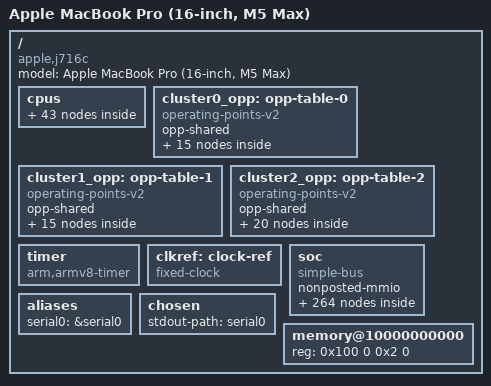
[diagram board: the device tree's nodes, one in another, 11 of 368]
/dts-v1/;


/ {
 compatible = "apple,t6050", "apple,arm-platform";
 #address-cells = <2>;
 #size-cells = <2>;
 cpus {
  #address-cells = <2>;
  #size-cells = <0>;
  cpu-map {
   cluster0 {
    core0 {
     cpu = <&cpu_m00>;
    };
    core1 {
     cpu = <&cpu_m01>;
    };
    core2 {
     cpu = <&cpu_m02>;
    };
    core3 {
     cpu = <&cpu_m03>;
    };
    core4 {
     cpu = <&cpu_m04>;
    };
    core5 {
     cpu = <&cpu_m05>;
    };
   };
   cluster1 {
    core0 {
     cpu = <&cpu_m10>;
    };
    core1 {
     cpu = <&cpu_m11>;
    };
    core2 {
     cpu = <&cpu_m12>;
    };
    core3 {
     cpu = <&cpu_m13>;
    };
    core4 {
     cpu = <&cpu_m14>;
    };
    core5 {
     cpu = <&cpu_m15>;
    };
   };
   cluster2 {
    core0 {
     cpu = <&cpu_p0>;
    };
    core1 {
     cpu = <&cpu_p1>;
    };
    core2 {
     cpu = <&cpu_p2>;
    };
    core3 {
     cpu = <&cpu_p3>;
    };
    core4 {
     cpu = <&cpu_p4>;
    };
    core5 {
     cpu = <&cpu_p5>;
    };
   };
  };
  cpu_m00: cpu@40000 {
   compatible = "apple,sotra-m";
   device_type = "cpu";
   reg = <0x0 0x40000>;
   enable-method = "spin-table";
   cpu-release-addr = <0 0>;
   next-level-cache = <&l2_cache_0>;
   i-cache-size = <0x20000>;
   d-cache-size = <0x10000>;
   operating-points-v2 = <&cluster0_opp>;
   performance-domains = <&cpufreq0>;
   capacity-dmips-mhz = <768>;
   dynamic-power-coefficient = <550>;
  };
  cpu_m01: cpu@40001 {
   compatible = "apple,sotra-m";
   device_type = "cpu";
   reg = <0x0 0x40001>;
   enable-method = "spin-table";
   cpu-release-addr = <0 0>;
   next-level-cache = <&l2_cache_0>;
   i-cache-size = <0x20000>;
   d-cache-size = <0x10000>;
   operating-points-v2 = <&cluster0_opp>;
   performance-domains = <&cpufreq0>;
   capacity-dmips-mhz = <768>;
   dynamic-power-coefficient = <550>;
  };
  cpu_m02: cpu@40002 {
   compatible = "apple,sotra-m";
   device_type = "cpu";
   reg = <0x0 0x40002>;
   enable-method = "spin-table";
   cpu-release-addr = <0 0>;
   next-level-cache = <&l2_cache_0>;
   i-cache-size = <0x20000>;
   d-cache-size = <0x10000>;
   operating-points-v2 = <&cluster0_opp>;
   performance-domains = <&cpufreq0>;
   capacity-dmips-mhz = <768>;
   dynamic-power-coefficient = <550>;
  };
  cpu_m03: cpu@40003 {
   compatible = "apple,sotra-m";
   device_type = "cpu";
   reg = <0x0 0x40003>;
   enable-method = "spin-table";
   cpu-release-addr = <0 0>;
   next-level-cache = <&l2_cache_0>;
   i-cache-size = <0x20000>;
   d-cache-size = <0x10000>;
   operating-points-v2 = <&cluster0_opp>;
   performance-domains = <&cpufreq0>;
   capacity-dmips-mhz = <768>;
   dynamic-power-coefficient = <550>;
  };
  cpu_m04: cpu@40004 {
   compatible = "apple,sotra-m";
   device_type = "cpu";
   reg = <0x0 0x40004>;
   enable-method = "spin-table";
   cpu-release-addr = <0 0>;
   next-level-cache = <&l2_cache_0>;
   i-cache-size = <0x20000>;
   d-cache-size = <0x10000>;
   operating-points-v2 = <&cluster0_opp>;
   performance-domains = <&cpufreq0>;
   capacity-dmips-mhz = <768>;
   dynamic-power-coefficient = <550>;
  };
  cpu_m05: cpu@40005 {
   compatible = "apple,sotra-m";
   device_type = "cpu";
   reg = <0x0 0x40005>;
   enable-method = "spin-table";
   cpu-release-addr = <0 0>;
   next-level-cache = <&l2_cache_0>;
   i-cache-size = <0x20000>;
   d-cache-size = <0x10000>;
   operating-points-v2 = <&cluster0_opp>;
   performance-domains = <&cpufreq0>;
   capacity-dmips-mhz = <768>;
   dynamic-power-coefficient = <550>;
  };
  cpu_m10: cpu@40100 {
   compatible = "apple,sotra-m";
   device_type = "cpu";
   reg = <0x0 0x40100>;
   enable-method = "spin-table";
   cpu-release-addr = <0 0>;
   next-level-cache = <&l2_cache_1>;
   i-cache-size = <0x20000>;
   d-cache-size = <0x10000>;
   operating-points-v2 = <&cluster1_opp>;
   performance-domains = <&cpufreq1>;
   capacity-dmips-mhz = <768>;
   dynamic-power-coefficient = <550>;
  };
  cpu_m11: cpu@40101 {
   compatible = "apple,sotra-m";
   device_type = "cpu";
   reg = <0x0 0x40101>;
   enable-method = "spin-table";
   cpu-release-addr = <0 0>;
   next-level-cache = <&l2_cache_1>;
   i-cache-size = <0x20000>;
   d-cache-size = <0x10000>;
   operating-points-v2 = <&cluster1_opp>;
   performance-domains = <&cpufreq1>;
   capacity-dmips-mhz = <768>;
   dynamic-power-coefficient = <550>;
  };
  cpu_m12: cpu@40102 {
   compatible = "apple,sotra-m";
   device_type = "cpu";
   reg = <0x0 0x40102>;
   enable-method = "spin-table";
   cpu-release-addr = <0 0>;
   next-level-cache = <&l2_cache_1>;
   i-cache-size = <0x20000>;
   d-cache-size = <0x10000>;
   operating-points-v2 = <&cluster1_opp>;
   performance-domains = <&cpufreq1>;
   capacity-dmips-mhz = <768>;
   dynamic-power-coefficient = <550>;
  };
  cpu_m13: cpu@40103 {
   compatible = "apple,sotra-m";
   device_type = "cpu";
   reg = <0x0 0x40103>;
   enable-method = "spin-table";
   cpu-release-addr = <0 0>;
   next-level-cache = <&l2_cache_1>;
   i-cache-size = <0x20000>;
   d-cache-size = <0x10000>;
   operating-points-v2 = <&cluster1_opp>;
   performance-domains = <&cpufreq1>;
   capacity-dmips-mhz = <768>;
   dynamic-power-coefficient = <550>;
  };
  cpu_m14: cpu@40104 {
   compatible = "apple,sotra-m";
   device_type = "cpu";
   reg = <0x0 0x40104>;
   enable-method = "spin-table";
   cpu-release-addr = <0 0>;
   next-level-cache = <&l2_cache_1>;
   i-cache-size = <0x20000>;
   d-cache-size = <0x10000>;
   operating-points-v2 = <&cluster1_opp>;
   performance-domains = <&cpufreq1>;
   capacity-dmips-mhz = <768>;
   dynamic-power-coefficient = <550>;
  };
  cpu_m15: cpu@40105 {
   compatible = "apple,sotra-m";
   device_type = "cpu";
   reg = <0x0 0x40105>;
   enable-method = "spin-table";
   cpu-release-addr = <0 0>;
   next-level-cache = <&l2_cache_1>;
   i-cache-size = <0x20000>;
   d-cache-size = <0x10000>;
   operating-points-v2 = <&cluster1_opp>;
   performance-domains = <&cpufreq1>;
   capacity-dmips-mhz = <768>;
   dynamic-power-coefficient = <550>;
  };
  cpu_p0: cpu@10200 {
   compatible = "apple,sotra-p";
   device_type = "cpu";
   reg = <0x0 0x10200>;
   enable-method = "spin-table";
   cpu-release-addr = <0 0>;
   next-level-cache = <&l2_cache_2>;
   i-cache-size = <0x30000>;
   d-cache-size = <0x20000>;
   operating-points-v2 = <&cluster2_opp>;
   performance-domains = <&cpufreq2>;
   capacity-dmips-mhz = <1024>;
   dynamic-power-coefficient = <1054>;
  };
  cpu_p1: cpu@10201 {
   compatible = "apple,sotra-p";
   device_type = "cpu";
   reg = <0x0 0x10201>;
   enable-method = "spin-table";
   cpu-release-addr = <0 0>;
   next-level-cache = <&l2_cache_2>;
   i-cache-size = <0x30000>;
   d-cache-size = <0x20000>;
   operating-points-v2 = <&cluster2_opp>;
   performance-domains = <&cpufreq2>;
   capacity-dmips-mhz = <1024>;
   dynamic-power-coefficient = <1054>;
  };
  cpu_p2: cpu@10202 {
   compatible = "apple,sotra-p";
   device_type = "cpu";
   reg = <0x0 0x10202>;
   enable-method = "spin-table";
   cpu-release-addr = <0 0>;
   next-level-cache = <&l2_cache_2>;
   i-cache-size = <0x30000>;
   d-cache-size = <0x20000>;
   operating-points-v2 = <&cluster2_opp>;
   performance-domains = <&cpufreq2>;
   capacity-dmips-mhz = <1024>;
   dynamic-power-coefficient = <1054>;
  };
  cpu_p3: cpu@10203 {
   compatible = "apple,sotra-p";
   device_type = "cpu";
   reg = <0x0 0x10203>;
   enable-method = "spin-table";
   cpu-release-addr = <0 0>;
   next-level-cache = <&l2_cache_2>;
   i-cache-size = <0x30000>;
   d-cache-size = <0x20000>;
   operating-points-v2 = <&cluster2_opp>;
   performance-domains = <&cpufreq2>;
   capacity-dmips-mhz = <1024>;
   dynamic-power-coefficient = <1054>;
  };
  cpu_p4: cpu@10204 {
   compatible = "apple,sotra-p";
   device_type = "cpu";
   reg = <0x0 0x10204>;
   enable-method = "spin-table";
   cpu-release-addr = <0 0>;
   next-level-cache = <&l2_cache_2>;
   i-cache-size = <0x30000>;
   d-cache-size = <0x20000>;
   operating-points-v2 = <&cluster2_opp>;
   performance-domains = <&cpufreq2>;
   capacity-dmips-mhz = <1024>;
   dynamic-power-coefficient = <1054>;
  };
  cpu_p5: cpu@10205 {
   compatible = "apple,sotra-p";
   device_type = "cpu";
   reg = <0x0 0x10205>;
   enable-method = "spin-table";
   cpu-release-addr = <0 0>;
   next-level-cache = <&l2_cache_2>;
   i-cache-size = <0x30000>;
   d-cache-size = <0x20000>;
   operating-points-v2 = <&cluster2_opp>;
   performance-domains = <&cpufreq2>;
   capacity-dmips-mhz = <1024>;
   dynamic-power-coefficient = <1054>;
  };
  l2_cache_0: l2-cache-0 {
   compatible = "cache";
   cache-level = <2>;
   cache-unified;
   cache-size = <0x800000>;
  };
  l2_cache_1: l2-cache-1 {
   compatible = "cache";
   cache-level = <2>;
   cache-unified;
   cache-size = <0x800000>;
  };
  l2_cache_2: l2-cache-2 {
   compatible = "cache";
   cache-level = <2>;
   cache-unified;
   cache-size = <0x1000000>;
  };
 };
 cluster0_opp: opp-table-0 {
  compatible = "operating-points-v2";
  opp-shared;
  opp01 {
   opp-hz = /bits/ 64 <1344000000>;
   opp-level = <1>;
   opp-microvolt = <600000>;
   clock-latency-ns = <50000>;
  };
  opp02 {
   opp-hz = /bits/ 64 <1644000000>;
   opp-level = <2>;
   opp-microvolt = <635000>;
   clock-latency-ns = <50000>;
  };
  opp03 {
   opp-hz = /bits/ 64 <1992000000>;
   opp-level = <3>;
   opp-microvolt = <665000>;
   clock-latency-ns = <50000>;
  };
  opp04 {
   opp-hz = /bits/ 64 <2304000000>;
   opp-level = <4>;
   opp-microvolt = <690000>;
   clock-latency-ns = <50000>;
  };
  opp05 {
   opp-hz = /bits/ 64 <2652000000>;
   opp-level = <5>;
   opp-microvolt = <740000>;
   clock-latency-ns = <50000>;
  };
  opp06 {
   opp-hz = /bits/ 64 <2964000000>;
   opp-level = <6>;
   opp-microvolt = <760000>;
   clock-latency-ns = <50000>;
  };
  opp07 {
   opp-hz = /bits/ 64 <3240000000>;
   opp-level = <7>;
   opp-microvolt = <800000>;
   clock-latency-ns = <50000>;
  };
  opp08 {
   opp-hz = /bits/ 64 <3504000000>;
   opp-level = <8>;
   opp-microvolt = <840000>;
   clock-latency-ns = <50000>;
  };
  opp09 {
   opp-hz = /bits/ 64 <3696000000>;
   opp-level = <9>;
   opp-microvolt = <880000>;
   clock-latency-ns = <50000>;
  };
  opp10 {
   opp-hz = /bits/ 64 <3876000000>;
   opp-level = <10>;
   opp-microvolt = <900000>;
   clock-latency-ns = <50000>;
  };
  opp11 {
   opp-hz = /bits/ 64 <4044000000>;
   opp-level = <11>;
   opp-microvolt = <970000>;
   clock-latency-ns = <50000>;
  };
  opp12 {
   opp-hz = /bits/ 64 <4176000000>;
   opp-level = <12>;
   opp-microvolt = <995000>;
   clock-latency-ns = <50000>;
  };
  opp13 {
   opp-hz = /bits/ 64 <4284000000>;
   opp-level = <13>;
   opp-microvolt = <1015000>;
   clock-latency-ns = <50000>;
  };
  opp14 {
   opp-hz = /bits/ 64 <4308000000>;
   opp-level = <14>;
   opp-microvolt = <1015000>;
   clock-latency-ns = <50000>;
  };
  opp15 {
   opp-hz = /bits/ 64 <4380000000>;
   opp-level = <15>;
   opp-microvolt = <1015000>;
   clock-latency-ns = <50000>;
  };
 };
 cluster1_opp: opp-table-1 {
  compatible = "operating-points-v2";
  opp-shared;
  opp01 {
   opp-hz = /bits/ 64 <1344000000>;
   opp-level = <1>;
   opp-microvolt = <600000>;
   clock-latency-ns = <50000>;
  };
  opp02 {
   opp-hz = /bits/ 64 <1644000000>;
   opp-level = <2>;
   opp-microvolt = <635000>;
   clock-latency-ns = <50000>;
  };
  opp03 {
   opp-hz = /bits/ 64 <1992000000>;
   opp-level = <3>;
   opp-microvolt = <665000>;
   clock-latency-ns = <50000>;
  };
  opp04 {
   opp-hz = /bits/ 64 <2304000000>;
   opp-level = <4>;
   opp-microvolt = <690000>;
   clock-latency-ns = <50000>;
  };
  opp05 {
   opp-hz = /bits/ 64 <2652000000>;
   opp-level = <5>;
   opp-microvolt = <740000>;
   clock-latency-ns = <50000>;
  };
  opp06 {
   opp-hz = /bits/ 64 <2964000000>;
   opp-level = <6>;
   opp-microvolt = <760000>;
   clock-latency-ns = <50000>;
  };
  opp07 {
   opp-hz = /bits/ 64 <3240000000>;
   opp-level = <7>;
   opp-microvolt = <800000>;
   clock-latency-ns = <50000>;
  };
  opp08 {
   opp-hz = /bits/ 64 <3504000000>;
   opp-level = <8>;
   opp-microvolt = <840000>;
   clock-latency-ns = <50000>;
  };
  opp09 {
   opp-hz = /bits/ 64 <3696000000>;
   opp-level = <9>;
   opp-microvolt = <880000>;
   clock-latency-ns = <50000>;
  };
  opp10 {
   opp-hz = /bits/ 64 <3876000000>;
   opp-level = <10>;
   opp-microvolt = <900000>;
   clock-latency-ns = <50000>;
  };
  opp11 {
   opp-hz = /bits/ 64 <4044000000>;
   opp-level = <11>;
   opp-microvolt = <970000>;
   clock-latency-ns = <50000>;
  };
  opp12 {
   opp-hz = /bits/ 64 <4176000000>;
   opp-level = <12>;
   opp-microvolt = <1005000>;
   clock-latency-ns = <50000>;
  };
  opp13 {
   opp-hz = /bits/ 64 <4284000000>;
   opp-level = <13>;
   opp-microvolt = <1025000>;
   clock-latency-ns = <50000>;
  };
  opp14 {
   opp-hz = /bits/ 64 <4308000000>;
   opp-level = <14>;
   opp-microvolt = <1025000>;
   clock-latency-ns = <50000>;
  };
  opp15 {
   opp-hz = /bits/ 64 <4380000000>;
   opp-level = <15>;
   opp-microvolt = <1025000>;
   clock-latency-ns = <50000>;
  };
 };
 cluster2_opp: opp-table-2 {
  compatible = "operating-points-v2";
  opp-shared;
  opp01 {
   opp-hz = /bits/ 64 <1308000000>;
   opp-level = <1>;
   opp-microvolt = <625000>;
   clock-latency-ns = <50000>;
  };
  opp02 {
   opp-hz = /bits/ 64 <1620000000>;
   opp-level = <2>;
   opp-microvolt = <675000>;
   clock-latency-ns = <50000>;
  };
  opp03 {
   opp-hz = /bits/ 64 <1980000000>;
   opp-level = <3>;
   opp-microvolt = <700000>;
   clock-latency-ns = <50000>;
  };
  opp04 {
   opp-hz = /bits/ 64 <2292000000>;
   opp-level = <4>;
   opp-microvolt = <735000>;
   clock-latency-ns = <50000>;
  };
  opp05 {
   opp-hz = /bits/ 64 <2580000000>;
   opp-level = <5>;
   opp-microvolt = <775000>;
   clock-latency-ns = <50000>;
  };
  opp06 {
   opp-hz = /bits/ 64 <2880000000>;
   opp-level = <6>;
   opp-microvolt = <810000>;
   clock-latency-ns = <50000>;
  };
  opp07 {
   opp-hz = /bits/ 64 <3180000000>;
   opp-level = <7>;
   opp-microvolt = <840000>;
   clock-latency-ns = <50000>;
  };
  opp08 {
   opp-hz = /bits/ 64 <3432000000>;
   opp-level = <8>;
   opp-microvolt = <875000>;
   clock-latency-ns = <50000>;
  };
  opp09 {
   opp-hz = /bits/ 64 <3648000000>;
   opp-level = <9>;
   opp-microvolt = <890000>;
   clock-latency-ns = <50000>;
  };
  opp10 {
   opp-hz = /bits/ 64 <3828000000>;
   opp-level = <10>;
   opp-microvolt = <925000>;
   clock-latency-ns = <50000>;
  };
  opp11 {
   opp-hz = /bits/ 64 <3984000000>;
   opp-level = <11>;
   opp-microvolt = <960000>;
   clock-latency-ns = <50000>;
  };
  opp12 {
   opp-hz = /bits/ 64 <4104000000>;
   opp-level = <12>;
   opp-microvolt = <980000>;
   clock-latency-ns = <50000>;
  };
  opp13 {
   opp-hz = /bits/ 64 <4188000000>;
   opp-level = <13>;
   opp-microvolt = <1030000>;
   clock-latency-ns = <50000>;
  };
  opp14 {
   opp-hz = /bits/ 64 <4236000000>;
   opp-level = <14>;
   opp-microvolt = <1030000>;
   clock-latency-ns = <50000>;
  };
  opp15 {
   opp-hz = /bits/ 64 <4284000000>;
   opp-level = <15>;
   opp-microvolt = <1030000>;
   clock-latency-ns = <50000>;
  };
  opp16 {
   opp-hz = /bits/ 64 <4308000000>;
   opp-level = <16>;
   opp-microvolt = <1030000>;
   clock-latency-ns = <50000>;
  };
  opp17 {
   opp-hz = /bits/ 64 <4332000000>;
   opp-level = <17>;
   opp-microvolt = <1030000>;
   clock-latency-ns = <50000>;
  };
  opp18 {
   opp-hz = /bits/ 64 <4428000000>;
   opp-level = <18>;
   opp-microvolt = <1030000>;
   clock-latency-ns = <50000>;
  };
  opp19 {
   opp-hz = /bits/ 64 <4512000000>;
   opp-level = <19>;
   opp-microvolt = <1090000>;
   clock-latency-ns = <50000>;
  };
  opp20 {
   opp-hz = /bits/ 64 <4608000000>;
   opp-level = <20>;
   opp-microvolt = <1090000>;
   clock-latency-ns = <50000>;
  };
 };
 timer {
  compatible = "arm,armv8-timer";
  interrupt-parent = <&aic>;
  interrupt-names = "phys", "virt", "hyp-phys", "hyp-virt";
  interrupts = <1 2 4>,
        <1 3 4>,
        <1 0 4>,
        <1 1 4>;
 };
 clkref: clock-ref {
  compatible = "fixed-clock";
  #clock-cells = <0>;
  clock-frequency = <24000000>;
  clock-output-names = "clkref";
 };
 soc: soc {
  compatible = "simple-bus";
  #address-cells = <2>;
  #size-cells = <2>;
  ranges;
  nonposted-mmio;
  cpufreq0: performance-controller@210e20000 {
   compatible = "apple,t6050-cluster-cpufreq", "apple,t8112-cluster-cpufreq";
   reg = <0x2 0x10e20000 0x0 0x1000>;
   #performance-domain-cells = <0>;
  };
  cpufreq1: performance-controller@211e20000 {
   compatible = "apple,t6050-cluster-cpufreq", "apple,t8112-cluster-cpufreq";
   reg = <0x2 0x11e20000 0x0 0x1000>;
   #performance-domain-cells = <0>;
  };
  cpufreq2: performance-controller@212e20000 {
   compatible = "apple,t6050-cluster-cpufreq", "apple,t8112-cluster-cpufreq";
   reg = <0x2 0x12e20000 0x0 0x1000>;
   #performance-domain-cells = <0>;
  };
  aic: interrupt-controller@280400000 {
   compatible = "apple,t6050-aic3", "apple,t8122-aic3";
   #interrupt-cells = <3>;
   interrupt-controller;
   reg = <0x2 0x80400000 0x0 0x1cc000>,
         <0x2 0x80440000 0x0 0x4000>;
   reg-names = "core", "event";
   power-domains = <&ps_aic>;
   affinities {
    m-core-pmu-affinity {
     apple,fiq-index = <4>;
     cpus = <&cpu_m00 &cpu_m01 &cpu_m02 &cpu_m03 &cpu_m04 &cpu_m05 &cpu_m10 &cpu_m11 &cpu_m12 &cpu_m13 &cpu_m14 &cpu_m15>;
    };
    p-core-pmu-affinity {
     apple,fiq-index = <5>;
     cpus = <&cpu_p0 &cpu_p1 &cpu_p2 &cpu_p3 &cpu_p4 &cpu_p5>;
    };
   };
  };
  pmgr: power-management@280600000 {
   compatible = "apple,t6050-pmgr", "apple,t8103-pmgr", "syscon", "simple-mfd";
   #address-cells = <1>;
   #size-cells = <1>;
   reg = <0x2 0x80600000 0x0 0x4000>;
  };
  pmgr1: power-management@280900000 {
   compatible = "apple,t6050-pmgr", "apple,t8103-pmgr", "syscon", "simple-mfd";
   #address-cells = <1>;
   #size-cells = <1>;
   reg = <0x2 0x80900000 0x0 0x4000>;
  };
  pinctrl_nub: pinctrl@2881e4000 {
   compatible = "apple,t6050-pinctrl", "apple,t8103-pinctrl";
   reg = <0x2 0x881e4000 0x0 0x4000>;
   power-domains = <&ps_nub_gpio>;
   gpio-controller;
   #gpio-cells = <2>;
   gpio-ranges = <&pinctrl_nub 0 0 61>;
   apple,npins = <61>;
   interrupt-controller;
   #interrupt-cells = <2>;
   interrupt-parent = <&aic>;
   interrupts = <0 706 4>,
         <0 708 4>,
         <0 710 4>,
         <0 712 4>,
         <0 714 4>,
         <0 716 4>,
         <0 718 4>;
  };
  pmgr_mini: power-management@288300000 {
   compatible = "apple,t6050-pmgr", "apple,t8103-pmgr", "syscon", "simple-mfd";
   #address-cells = <1>;
   #size-cells = <1>;
   reg = <0x2 0x88300000 0x0 0xc000>;
  };
  wdt: watchdog@28836c000 {
   compatible = "apple,t6050-wdt", "apple,t8103-wdt";
   reg = <0x2 0x8836c000 0x0 0x4000>;
   clocks = <&clkref>;
   interrupt-parent = <&aic>;
   interrupts = <0 721 4>;
  };
  smc: smc@28c600000 {
   compatible = "apple,t6050-smc", "apple,t8103-smc";
   reg = <0x2 0x8c600000 0x0 0x4000>,
         <0x2 0x8e000000 0x0 0x100000>;
   reg-names = "smc", "sram";
   mboxes = <&smc_mbox>;
   status = "disabled";
   smc_gpio: gpio {
    compatible = "apple,smc-gpio";
    gpio-controller;
    #gpio-cells = <2>;
   };
   smc_hwmon: hwmon {
    compatible = "apple,smc-hwmon";
   };
  };
  smc_mbox: mbox@28c608000 {
   compatible = "apple,t6050-asc-mailbox", "apple,asc-mailbox-v4";
   reg = <0x2 0x8c608000 0x0 0x4000>;
   interrupt-parent = <&aic>;
   interrupts = <0 899 4>,
         <0 900 4>,
         <0 901 4>,
         <0 902 4>;
   interrupt-names = "send-empty", "send-not-empty",
       "recv-empty", "recv-not-empty";
   #mbox-cells = <0>;
  };
  pinctrl_aop: pinctrl@290824000 {
   compatible = "apple,t6050-pinctrl", "apple,t8103-pinctrl";
   reg = <0x2 0x90824000 0x0 0x4000>;
   gpio-controller;
   #gpio-cells = <2>;
   gpio-ranges = <&pinctrl_aop 0 0 85>;
   apple,npins = <85>;
   interrupt-controller;
   #interrupt-cells = <2>;
   interrupt-parent = <&aic>;
   interrupts = <0 568 4>,
         <0 569 4>,
         <0 570 4>,
         <0 571 4>,
         <0 572 4>,
         <0 573 4>,
         <0 574 4>;
  };
  dart_mtp: iommu@294800000 {
   compatible = "apple,t6050-dart", "apple,t8110-dart";
   reg = <0x2 0x94800000 0x0 0xc000>;
   #iommu-cells = <1>;
   interrupt-parent = <&aic>;
   interrupts = <0 659 4>;
   status = "disabled";
  };
  pinctrl_ap: pinctrl@29c000000 {
   compatible = "apple,t6050-pinctrl", "apple,t8103-pinctrl";
   reg = <0x2 0x9c000000 0x0 0x44000>;
   power-domains = <&ps_gpio>;
   gpio-controller;
   #gpio-cells = <2>;
   gpio-ranges = <&pinctrl_ap 0 0 221>;
   apple,npins = <221>;
   interrupt-controller;
   #interrupt-cells = <2>;
   interrupt-parent = <&aic>;
   interrupts = <0 486 4>,
         <0 487 4>,
         <0 488 4>,
         <0 489 4>,
         <0 490 4>,
         <0 491 4>,
         <0 492 4>;
  };
  dart_acio0: iommu@2a1a80000 {
   compatible = "apple,t6050-dart", "apple,t8110-dart";
   reg = <0x2 0xa1a80000 0x0 0xc000>;
   #iommu-cells = <1>;
   interrupt-parent = <&aic>;
   interrupts = <0 1606 4>;
   status = "disabled";
  };
  dart_usb0_0: iommu@2a2f00000 {
   compatible = "apple,t6050-dart", "apple,t8110-dart";
   reg = <0x2 0xa2f00000 0x0 0xc000>;
   #iommu-cells = <1>;
   interrupt-parent = <&aic>;
   interrupts = <0 1423 4>;
   power-domains = <&ps_atc0_usb>;
   status = "disabled";
  };
  dart_usb0_1: iommu@2a2f80000 {
   compatible = "apple,t6050-dart", "apple,t8110-dart";
   reg = <0x2 0xa2f80000 0x0 0xc000>;
   #iommu-cells = <1>;
   interrupt-parent = <&aic>;
   interrupts = <0 1423 4>;
   power-domains = <&ps_atc0_usb>;
   status = "disabled";
  };
  dart_apciec0: iommu@2a4000000 {
   compatible = "apple,t6050-dart", "apple,t8110-dart";
   reg = <0x2 0xa4000000 0x0 0x20000>;
   #iommu-cells = <1>;
   interrupt-parent = <&aic>;
   interrupts = <0 1406 4>;
   status = "disabled";
  };
  dart_acio1: iommu@2a9a80000 {
   compatible = "apple,t6050-dart", "apple,t8110-dart";
   reg = <0x2 0xa9a80000 0x0 0xc000>;
   #iommu-cells = <1>;
   interrupt-parent = <&aic>;
   interrupts = <0 1638 4>;
   status = "disabled";
  };
  dart_usb1_0: iommu@2aaf00000 {
   compatible = "apple,t6050-dart", "apple,t8110-dart";
   reg = <0x2 0xaaf00000 0x0 0xc000>;
   #iommu-cells = <1>;
   interrupt-parent = <&aic>;
   interrupts = <0 1455 4>;
   power-domains = <&ps_atc1_usb>;
   status = "disabled";
  };
  dart_usb1_1: iommu@2aaf80000 {
   compatible = "apple,t6050-dart", "apple,t8110-dart";
   reg = <0x2 0xaaf80000 0x0 0xc000>;
   #iommu-cells = <1>;
   interrupt-parent = <&aic>;
   interrupts = <0 1455 4>;
   power-domains = <&ps_atc1_usb>;
   status = "disabled";
  };
  dart_apciec1: iommu@2ac000000 {
   compatible = "apple,t6050-dart", "apple,t8110-dart";
   reg = <0x2 0xac000000 0x0 0x20000>;
   #iommu-cells = <1>;
   interrupt-parent = <&aic>;
   interrupts = <0 1438 4>;
   status = "disabled";
  };
  dart_dispext0_isoc: iommu@2b2180000 {
   compatible = "apple,t6050-dart", "apple,t8110-dart";
   reg = <0x2 0xb2180000 0x0 0x20000>;
   #iommu-cells = <1>;
   interrupt-parent = <&aic>;
   interrupts = <0 1093 4>;
   status = "disabled";
  };
  dart_dispext0: iommu@2b2300000 {
   compatible = "apple,t6050-dart", "apple,t8110-dart";
   reg = <0x2 0xb2300000 0x0 0xc000>;
   #iommu-cells = <1>;
   interrupt-parent = <&aic>;
   interrupts = <0 1070 4>;
   status = "disabled";
  };
  dart_dcpext0: iommu@2b2340000 {
   compatible = "apple,t6050-dart", "apple,t8110-dart";
   reg = <0x2 0xb2340000 0x0 0x20000>;
   #iommu-cells = <1>;
   interrupt-parent = <&aic>;
   interrupts = <0 1070 4>;
   status = "disabled";
  };
  dart_dispext2_isoc: iommu@302180000 {
   compatible = "apple,t6050-dart", "apple,t8110-dart";
   reg = <0x3 0x02180000 0x0 0x20000>;
   #iommu-cells = <1>;
   interrupt-parent = <&aic>;
   interrupts = <0 1237 4>;
   status = "disabled";
  };
  dart_dispext2: iommu@302300000 {
   compatible = "apple,t6050-dart", "apple,t8110-dart";
   reg = <0x3 0x02300000 0x0 0xc000>;
   #iommu-cells = <1>;
   interrupt-parent = <&aic>;
   interrupts = <0 1214 4>;
   status = "disabled";
  };
  dart_dcpext2: iommu@302340000 {
   compatible = "apple,t6050-dart", "apple,t8110-dart";
   reg = <0x3 0x02340000 0x0 0x20000>;
   #iommu-cells = <1>;
   interrupt-parent = <&aic>;
   interrupts = <0 1214 4>;
   status = "disabled";
  };
  dart_dispext3_isoc: iommu@306180000 {
   compatible = "apple,t6050-dart", "apple,t8110-dart";
   reg = <0x3 0x06180000 0x0 0x20000>;
   #iommu-cells = <1>;
   interrupt-parent = <&aic>;
   interrupts = <0 1309 4>;
   status = "disabled";
  };
  dart_dispext3: iommu@306300000 {
   compatible = "apple,t6050-dart", "apple,t8110-dart";
   reg = <0x3 0x06300000 0x0 0xc000>;
   #iommu-cells = <1>;
   interrupt-parent = <&aic>;
   interrupts = <0 1286 4>;
   status = "disabled";
  };
  dart_dcpext3: iommu@306340000 {
   compatible = "apple,t6050-dart", "apple,t8110-dart";
   reg = <0x3 0x06340000 0x0 0x20000>;
   #iommu-cells = <1>;
   interrupt-parent = <&aic>;
   interrupts = <0 1286 4>;
   status = "disabled";
  };
  dart_acio2: iommu@381a80000 {
   compatible = "apple,t6050-dart", "apple,t8110-dart";
   reg = <0x3 0x81a80000 0x0 0xc000>;
   #iommu-cells = <1>;
   interrupt-parent = <&aic>;
   interrupts = <0 1670 4>;
   status = "disabled";
  };
  dart_usb2_0: iommu@382f00000 {
   compatible = "apple,t6050-dart", "apple,t8110-dart";
   reg = <0x3 0x82f00000 0x0 0xc000>;
   #iommu-cells = <1>;
   interrupt-parent = <&aic>;
   interrupts = <0 1487 4>;
   power-domains = <&ps_atc2_usb>;
   status = "disabled";
  };
  dart_usb2_1: iommu@382f80000 {
   compatible = "apple,t6050-dart", "apple,t8110-dart";
   reg = <0x3 0x82f80000 0x0 0xc000>;
   #iommu-cells = <1>;
   interrupt-parent = <&aic>;
   interrupts = <0 1487 4>;
   power-domains = <&ps_atc2_usb>;
   status = "disabled";
  };
  dart_apciec2: iommu@384000000 {
   compatible = "apple,t6050-dart", "apple,t8110-dart";
   reg = <0x3 0x84000000 0x0 0x20000>;
   #iommu-cells = <1>;
   interrupt-parent = <&aic>;
   interrupts = <0 1470 4>;
   status = "disabled";
  };
  dart_dispext1_isoc: iommu@392180000 {
   compatible = "apple,t6050-dart", "apple,t8110-dart";
   reg = <0x3 0x92180000 0x0 0x20000>;
   #iommu-cells = <1>;
   interrupt-parent = <&aic>;
   interrupts = <0 1165 4>;
   status = "disabled";
  };
  dart_dispext1: iommu@392300000 {
   compatible = "apple,t6050-dart", "apple,t8110-dart";
   reg = <0x3 0x92300000 0x0 0xc000>;
   #iommu-cells = <1>;
   interrupt-parent = <&aic>;
   interrupts = <0 1142 4>;
   status = "disabled";
  };
  dart_dcpext1: iommu@392340000 {
   compatible = "apple,t6050-dart", "apple,t8110-dart";
   reg = <0x3 0x92340000 0x0 0x20000>;
   #iommu-cells = <1>;
   interrupt-parent = <&aic>;
   interrupts = <0 1142 4>;
   status = "disabled";
  };
  dart_auss0: iommu@395d60000 {
   compatible = "apple,t6050-dart", "apple,t8110-dart";
   reg = <0x3 0x95d60000 0x0 0xc000>;
   #iommu-cells = <1>;
   interrupt-parent = <&aic>;
   interrupts = <0 2343 4>;
   status = "disabled";
  };
  dart_apcie0: iommu@410000000 {
   compatible = "apple,t6050-dart", "apple,t8110-dart";
   reg = <0x4 0x10000000 0x0 0x20000>;
   #iommu-cells = <1>;
   interrupt-parent = <&aic>;
   interrupts = <0 1524 4>;
   status = "disabled";
  };
  dart_apcie1: iommu@411000000 {
   compatible = "apple,t6050-dart", "apple,t8110-dart";
   reg = <0x4 0x11000000 0x0 0x20000>;
   #iommu-cells = <1>;
   interrupt-parent = <&aic>;
   interrupts = <0 1532 4>;
   status = "disabled";
  };
  ans_mbox: mbox@419608000 {
   compatible = "apple,t6050-asc-mailbox", "apple,asc-mailbox-v4";
   reg = <0x4 0x19608000 0x0 0x4000>;
   interrupt-parent = <&aic>;
   interrupts = <0 1347 4>,
         <0 1348 4>,
         <0 1349 4>,
         <0 1350 4>;
   interrupt-names = "send-empty", "send-not-empty",
       "recv-empty", "recv-not-empty";
   power-domains = <&ps_ans>;
   #mbox-cells = <0>;
  };
  sart: iommu@41dc50000 {
   compatible = "apple,t6050-sart";
   reg = <0x4 0x1dc50000 0x0 0xc000>;
   power-domains = <&ps_ans>;
  };
  nvme: nvme@45dcc0000 {
   compatible = "apple,t6050-nvme-ans2", "apple,t8132-nvme-ans2";
   reg = <0x4 0x5dcc0000 0x0 0x40000>,
         <0x4 0x19600000 0x0 0x4000>,
         <0x4 0x1dcc0000 0x0 0x60010>;
   reg-names = "nvme", "ans", "nvmmu";
   interrupt-parent = <&aic>;
   interrupts = <0 2338 4>;
   mboxes = <&ans_mbox>;
   apple,sart = <&sart>;
   power-domains = <&ps_ans>, <&ps_apcie_sys_st0>, <&ps_apcie_sys_st1>;
   power-domain-names = "ans", "apcie0", "apcie1";
   resets = <&ps_ans>;
   status = "disabled";
  };
  dart_disp0_isoc: iommu@48a180000 {
   compatible = "apple,t6050-dart", "apple,t8110-dart";
   reg = <0x4 0x8a180000 0x0 0x20000>;
   #iommu-cells = <1>;
   interrupt-parent = <&aic>;
   interrupts = <0 1013 4>;
   status = "disabled";
  };
  dart_disp0: iommu@48a300000 {
   compatible = "apple,t6050-dart", "apple,t8110-dart";
   reg = <0x4 0x8a300000 0x0 0xc000>;
   #iommu-cells = <1>;
   interrupt-parent = <&aic>;
   interrupts = <0 990 4>;
   status = "disabled";
  };
  dart_dcp: iommu@48a340000 {
   compatible = "apple,t6050-dart", "apple,t8110-dart";
   reg = <0x4 0x8a340000 0x0 0x20000>;
   #iommu-cells = <1>;
   interrupt-parent = <&aic>;
   interrupts = <0 990 4>;
   status = "disabled";
  };
  dart_apr0: iommu@48d020000 {
   compatible = "apple,t6050-dart", "apple,t8110-dart";
   reg = <0x4 0x8d020000 0x0 0xc000>;
   #iommu-cells = <1>;
   interrupt-parent = <&aic>;
   interrupts = <0 1712 4>;
   power-domains = <&ps_scodec>;
   status = "disabled";
  };
  i2c0: i2c@505010000 {
   compatible = "apple,t6050-i2c", "apple,t8103-i2c";
   reg = <0x5 0x05010000 0x0 0x4000>;
   clocks = <&clkref>;
   interrupt-parent = <&aic>;
   interrupts = <0 1375 4>;
   #address-cells = <0x1>;
   #size-cells = <0x0>;
   power-domains = <&ps_i2c0>;
   status = "disabled";
  };
  i2c1: i2c@505014000 {
   compatible = "apple,t6050-i2c", "apple,t8103-i2c";
   reg = <0x5 0x05014000 0x0 0x4000>;
   clocks = <&clkref>;
   interrupt-parent = <&aic>;
   interrupts = <0 1376 4>;
   #address-cells = <0x1>;
   #size-cells = <0x0>;
   power-domains = <&ps_i2c1>;
   status = "disabled";
  };
  i2c2: i2c@505018000 {
   compatible = "apple,t6050-i2c", "apple,t8103-i2c";
   reg = <0x5 0x05018000 0x0 0x4000>;
   clocks = <&clkref>;
   interrupt-parent = <&aic>;
   interrupts = <0 1377 4>;
   #address-cells = <0x1>;
   #size-cells = <0x0>;
   power-domains = <&ps_i2c2>;
   status = "disabled";
  };
  i2c3: i2c@50501c000 {
   compatible = "apple,t6050-i2c", "apple,t8103-i2c";
   reg = <0x5 0x0501c000 0x0 0x4000>;
   clocks = <&clkref>;
   interrupt-parent = <&aic>;
   interrupts = <0 1378 4>;
   #address-cells = <0x1>;
   #size-cells = <0x0>;
   power-domains = <&ps_i2c3>;
   status = "disabled";
  };
  i2c4: i2c@505020000 {
   compatible = "apple,t6050-i2c", "apple,t8103-i2c";
   reg = <0x5 0x05020000 0x0 0x4000>;
   clocks = <&clkref>;
   interrupt-parent = <&aic>;
   interrupts = <0 1379 4>;
   #address-cells = <0x1>;
   #size-cells = <0x0>;
   power-domains = <&ps_i2c4>;
   status = "disabled";
  };
  i2c5: i2c@505024000 {
   compatible = "apple,t6050-i2c", "apple,t8103-i2c";
   reg = <0x5 0x05024000 0x0 0x4000>;
   clocks = <&clkref>;
   interrupt-parent = <&aic>;
   interrupts = <0 1380 4>;
   #address-cells = <0x1>;
   #size-cells = <0x0>;
   power-domains = <&ps_i2c5>;
   status = "disabled";
  };
  i2c6: i2c@505028000 {
   compatible = "apple,t6050-i2c", "apple,t8103-i2c";
   reg = <0x5 0x05028000 0x0 0x4000>;
   clocks = <&clkref>;
   interrupt-parent = <&aic>;
   interrupts = <0 1381 4>;
   #address-cells = <0x1>;
   #size-cells = <0x0>;
   power-domains = <&ps_i2c6>;
   status = "disabled";
  };
  i2c7: i2c@50502c000 {
   compatible = "apple,t6050-i2c", "apple,t8103-i2c";
   reg = <0x5 0x0502c000 0x0 0x4000>;
   clocks = <&clkref>;
   interrupt-parent = <&aic>;
   interrupts = <0 1382 4>;
   #address-cells = <0x1>;
   #size-cells = <0x0>;
   power-domains = <&ps_i2c7>;
   status = "disabled";
  };
  i2c8: i2c@505030000 {
   compatible = "apple,t6050-i2c", "apple,t8103-i2c";
   reg = <0x5 0x05030000 0x0 0x4000>;
   clocks = <&clkref>;
   interrupt-parent = <&aic>;
   interrupts = <0 1383 4>;
   #address-cells = <0x1>;
   #size-cells = <0x0>;
   power-domains = <&ps_i2c8>;
   status = "disabled";
  };
  dart_sio: iommu@505060000 {
   compatible = "apple,t6050-dart", "apple,t8110-dart";
   reg = <0x5 0x05060000 0x0 0x20000>;
   #iommu-cells = <1>;
   interrupt-parent = <&aic>;
   interrupts = <0 1387 4>;
   power-domains = <&ps_sio>;
   status = "disabled";
  };
  serial0: serial@505200000 {
   compatible = "apple,s5l-uart";
   reg = <0x5 0x05200000 0x0 0x4000>;
   reg-io-width = <4>;
   interrupt-parent = <&aic>;
   interrupts = <0 1359 4>;
   clocks = <&clkref>, <&clkref>;
   clock-names = "uart", "clk_uart_baud0";
   power-domains = <&ps_uart0>;
   status = "disabled";
  };
  dart_jpeg0: iommu@2281020000 {
   compatible = "apple,t6050-dart", "apple,t8110-dart";
   reg = <0x22 0x81020000 0x0 0xc000>;
   #iommu-cells = <1>;
   interrupt-parent = <&aic>;
   interrupts = <0 1356 4>;
   power-domains = <&ps_jpg>;
   status = "disabled";
  };
  dart_ave0_1: iommu@2283080000 {
   compatible = "apple,t6050-dart", "apple,t8110-dart";
   reg = <0x22 0x83080000 0x0 0xc000>;
   #iommu-cells = <1>;
   interrupt-parent = <&aic>;
   interrupts = <0 2432 4>;
   power-domains = <&ps_venc0_sys>;
   status = "disabled";
  };
  dart_ave0_0: iommu@22830a0000 {
   compatible = "apple,t6050-dart", "apple,t8110-dart";
   reg = <0x22 0x830a0000 0x0 0xc000>;
   #iommu-cells = <1>;
   interrupt-parent = <&aic>;
   interrupts = <0 2432 4>;
   power-domains = <&ps_venc0_sys>;
   status = "disabled";
  };
  dart_scaler0: iommu@2285260000 {
   compatible = "apple,t6050-dart", "apple,t8110-dart";
   reg = <0x22 0x85260000 0x0 0x20000>;
   #iommu-cells = <1>;
   interrupt-parent = <&aic>;
   interrupts = <0 2469 4>;
   power-domains = <&ps_msr0>;
   status = "disabled";
  };
  pmgr_gfx: power-management@2300e80000 {
   compatible = "apple,t6050-pmgr", "apple,t8103-pmgr", "syscon", "simple-mfd";
   #address-cells = <1>;
   #size-cells = <1>;
   reg = <0x23 0x00e80000 0x0 0x4000>;
  };
  dart_avd0: iommu@2309020000 {
   compatible = "apple,t6050-dart", "apple,t8110-dart";
   reg = <0x23 0x09020000 0x0 0x20000>;
   #iommu-cells = <1>;
   interrupt-parent = <&aic>;
   interrupts = <0 2424 4>;
   power-domains = <&ps_avd_sys>;
   status = "disabled";
  };
  dart_apr1: iommu@230b020000 {
   compatible = "apple,t6050-dart", "apple,t8110-dart";
   reg = <0x23 0x0b020000 0x0 0xc000>;
   #iommu-cells = <1>;
   interrupt-parent = <&aic>;
   interrupts = <0 1760 4>;
   power-domains = <&ps_prores>;
   status = "disabled";
  };
  pmgr_die1: power-management@2380600000 {
   compatible = "apple,t6050-pmgr", "apple,t8103-pmgr", "syscon", "simple-mfd";
   #address-cells = <1>;
   #size-cells = <1>;
   reg = <0x23 0x80600000 0x0 0xc000>;
  };
  pmgr_die1_mini: power-management@2388300000 {
   compatible = "apple,t6050-pmgr", "apple,t8103-pmgr", "syscon", "simple-mfd";
   #address-cells = <1>;
   #size-cells = <1>;
   reg = <0x23 0x88300000 0x0 0x4000>;
  };
  dart_scaler1: iommu@23a1260000 {
   compatible = "apple,t6050-dart", "apple,t8110-dart";
   reg = <0x23 0xa1260000 0x0 0x20000>;
   #iommu-cells = <1>;
   interrupt-parent = <&aic>;
   interrupts = <0 2493 4>;
   power-domains = <&ps_msr1>;
   status = "disabled";
  };
  dart_ave1_1: iommu@23a3080000 {
   compatible = "apple,t6050-dart", "apple,t8110-dart";
   reg = <0x23 0xa3080000 0x0 0xc000>;
   #iommu-cells = <1>;
   interrupt-parent = <&aic>;
   interrupts = <0 2440 4>;
   power-domains = <&ps_venc1_sys>;
   status = "disabled";
  };
  dart_ave1_0: iommu@23a30a0000 {
   compatible = "apple,t6050-dart", "apple,t8110-dart";
   reg = <0x23 0xa30a0000 0x0 0xc000>;
   #iommu-cells = <1>;
   interrupt-parent = <&aic>;
   interrupts = <0 2440 4>;
   power-domains = <&ps_venc1_sys>;
   status = "disabled";
  };
 };
};
&pmgr {
 ps_aic: power-controller@108 {
  compatible = "apple,t6050-pmgr-pwrstate", "apple,t8103-pmgr-pwrstate";
  reg = <0x108 4>;
  #power-domain-cells = <0>;
  #reset-cells = <0>;
  label = "aic";
  apple,always-on;
 };
 ps_pmc: power-controller@110 {
  compatible = "apple,t6050-pmgr-pwrstate", "apple,t8103-pmgr-pwrstate";
  reg = <0x110 4>;
  #power-domain-cells = <0>;
  #reset-cells = <0>;
  label = "pmc";
  apple,always-on;
 };
 ps_pms_c1ppt: power-controller@118 {
  compatible = "apple,t6050-pmgr-pwrstate", "apple,t8103-pmgr-pwrstate";
  reg = <0x118 4>;
  #power-domain-cells = <0>;
  #reset-cells = <0>;
  label = "pms_c1ppt";
  apple,always-on;
 };
 ps_soc_dpe: power-controller@120 {
  compatible = "apple,t6050-pmgr-pwrstate", "apple,t8103-pmgr-pwrstate";
  reg = <0x120 4>;
  #power-domain-cells = <0>;
  #reset-cells = <0>;
  label = "soc_dpe";
  apple,always-on;
 };
 ps_pmp: power-controller@128 {
  compatible = "apple,t6050-pmgr-pwrstate", "apple,t8103-pmgr-pwrstate";
  reg = <0x128 4>;
  #power-domain-cells = <0>;
  #reset-cells = <0>;
  label = "pmp";
  apple,always-on;
 };
 ps_pms_sram: power-controller@130 {
  compatible = "apple,t6050-pmgr-pwrstate", "apple,t8103-pmgr-pwrstate";
  reg = <0x130 4>;
  #power-domain-cells = <0>;
  #reset-cells = <0>;
  label = "pms_sram";
  apple,always-on;
 };
 ps_dispext0_sys: power-controller@200 {
  compatible = "apple,t6050-pmgr-pwrstate", "apple,t8103-pmgr-pwrstate";
  reg = <0x200 4>;
  #power-domain-cells = <0>;
  #reset-cells = <0>;
  label = "dispext0_sys";
 };
 ps_atc0_common: power-controller@208 {
  compatible = "apple,t6050-pmgr-pwrstate", "apple,t8103-pmgr-pwrstate";
  reg = <0x208 4>;
  #power-domain-cells = <0>;
  #reset-cells = <0>;
  label = "atc0_common";
 };
 ps_atc1_common: power-controller@210 {
  compatible = "apple,t6050-pmgr-pwrstate", "apple,t8103-pmgr-pwrstate";
  reg = <0x210 4>;
  #power-domain-cells = <0>;
  #reset-cells = <0>;
  label = "atc1_common";
 };
 ps_dispext2_sys: power-controller@220 {
  compatible = "apple,t6050-pmgr-pwrstate", "apple,t8103-pmgr-pwrstate";
  reg = <0x220 4>;
  #power-domain-cells = <0>;
  #reset-cells = <0>;
  label = "dispext2_sys";
 };
 ps_dispext3_sys: power-controller@228 {
  compatible = "apple,t6050-pmgr-pwrstate", "apple,t8103-pmgr-pwrstate";
  reg = <0x228 4>;
  #power-domain-cells = <0>;
  #reset-cells = <0>;
  label = "dispext3_sys";
 };
 ps_dispext1_sys: power-controller@230 {
  compatible = "apple,t6050-pmgr-pwrstate", "apple,t8103-pmgr-pwrstate";
  reg = <0x230 4>;
  #power-domain-cells = <0>;
  #reset-cells = <0>;
  label = "dispext1_sys";
 };
 ps_atc2_common: power-controller@238 {
  compatible = "apple,t6050-pmgr-pwrstate", "apple,t8103-pmgr-pwrstate";
  reg = <0x238 4>;
  #power-domain-cells = <0>;
  #reset-cells = <0>;
  label = "atc2_common";
 };
 ps_atc3_common: power-controller@240 {
  compatible = "apple,t6050-pmgr-pwrstate", "apple,t8103-pmgr-pwrstate";
  reg = <0x240 4>;
  #power-domain-cells = <0>;
  #reset-cells = <0>;
  label = "atc3_common";
 };
 ps_auss: power-controller@248 {
  compatible = "apple,t6050-pmgr-pwrstate", "apple,t8103-pmgr-pwrstate";
  reg = <0x248 4>;
  #power-domain-cells = <0>;
  #reset-cells = <0>;
  label = "auss";
 };
 ps_gpio: power-controller@250 {
  compatible = "apple,t6050-pmgr-pwrstate", "apple,t8103-pmgr-pwrstate";
  reg = <0x250 4>;
  #power-domain-cells = <0>;
  #reset-cells = <0>;
  label = "gpio";
 };
 ps_msg: power-controller@258 {
  compatible = "apple,t6050-pmgr-pwrstate", "apple,t8103-pmgr-pwrstate";
  reg = <0x258 4>;
  #power-domain-cells = <0>;
  #reset-cells = <0>;
  label = "msg";
 };
 ps_ap_tmm: power-controller@260 {
  compatible = "apple,t6050-pmgr-pwrstate", "apple,t8103-pmgr-pwrstate";
  reg = <0x260 4>;
  #power-domain-cells = <0>;
  #reset-cells = <0>;
  label = "ap_tmm";
 };
 ps_dispext0_fe: power-controller@268 {
  compatible = "apple,t6050-pmgr-pwrstate", "apple,t8103-pmgr-pwrstate";
  reg = <0x268 4>;
  #power-domain-cells = <0>;
  #reset-cells = <0>;
  label = "dispext0_fe";
  power-domains = <&ps_dispext0_sys>;
 };
 ps_dispext0_adma: power-controller@270 {
  compatible = "apple,t6050-pmgr-pwrstate", "apple,t8103-pmgr-pwrstate";
  reg = <0x270 4>;
  #power-domain-cells = <0>;
  #reset-cells = <0>;
  label = "dispext0_adma";
  power-domains = <&ps_dispext0_sys>;
 };
 ps_dispext0_cpu: power-controller@278 {
  compatible = "apple,t6050-pmgr-pwrstate", "apple,t8103-pmgr-pwrstate";
  reg = <0x278 4>;
  #power-domain-cells = <0>;
  #reset-cells = <0>;
  label = "dispext0_cpu";
  power-domains = <&ps_dispext0_fe>;
  status = "disabled";
 };
 ps_atc0_cio: power-controller@280 {
  compatible = "apple,t6050-pmgr-pwrstate", "apple,t8103-pmgr-pwrstate";
  reg = <0x280 4>;
  #power-domain-cells = <0>;
  #reset-cells = <0>;
  label = "atc0_cio";
  power-domains = <&ps_atc0_common>;
 };
 ps_atc0_pcie: power-controller@288 {
  compatible = "apple,t6050-pmgr-pwrstate", "apple,t8103-pmgr-pwrstate";
  reg = <0x288 4>;
  #power-domain-cells = <0>;
  #reset-cells = <0>;
  label = "atc0_pcie";
  power-domains = <&ps_atc0_common>;
 };
 ps_atc1_cio: power-controller@290 {
  compatible = "apple,t6050-pmgr-pwrstate", "apple,t8103-pmgr-pwrstate";
  reg = <0x290 4>;
  #power-domain-cells = <0>;
  #reset-cells = <0>;
  label = "atc1_cio";
  power-domains = <&ps_atc1_common>;
 };
 ps_atc1_pcie: power-controller@298 {
  compatible = "apple,t6050-pmgr-pwrstate", "apple,t8103-pmgr-pwrstate";
  reg = <0x298 4>;
  #power-domain-cells = <0>;
  #reset-cells = <0>;
  label = "atc1_pcie";
  power-domains = <&ps_atc1_common>;
 };
 ps_dispext2_fe: power-controller@2a0 {
  compatible = "apple,t6050-pmgr-pwrstate", "apple,t8103-pmgr-pwrstate";
  reg = <0x2a0 4>;
  #power-domain-cells = <0>;
  #reset-cells = <0>;
  label = "dispext2_fe";
  power-domains = <&ps_dispext2_sys>;
 };
 ps_dispext2_adma: power-controller@2a8 {
  compatible = "apple,t6050-pmgr-pwrstate", "apple,t8103-pmgr-pwrstate";
  reg = <0x2a8 4>;
  #power-domain-cells = <0>;
  #reset-cells = <0>;
  label = "dispext2_adma";
  power-domains = <&ps_dispext2_sys>;
 };
 ps_dispext2_cpu: power-controller@2b0 {
  compatible = "apple,t6050-pmgr-pwrstate", "apple,t8103-pmgr-pwrstate";
  reg = <0x2b0 4>;
  #power-domain-cells = <0>;
  #reset-cells = <0>;
  label = "dispext2_cpu";
  power-domains = <&ps_dispext2_fe>;
  status = "disabled";
 };
 ps_dispext3_fe: power-controller@2b8 {
  compatible = "apple,t6050-pmgr-pwrstate", "apple,t8103-pmgr-pwrstate";
  reg = <0x2b8 4>;
  #power-domain-cells = <0>;
  #reset-cells = <0>;
  label = "dispext3_fe";
  power-domains = <&ps_dispext3_sys>;
 };
 ps_dispext3_adma: power-controller@2c0 {
  compatible = "apple,t6050-pmgr-pwrstate", "apple,t8103-pmgr-pwrstate";
  reg = <0x2c0 4>;
  #power-domain-cells = <0>;
  #reset-cells = <0>;
  label = "dispext3_adma";
  power-domains = <&ps_dispext3_sys>;
 };
 ps_dispext3_cpu: power-controller@2c8 {
  compatible = "apple,t6050-pmgr-pwrstate", "apple,t8103-pmgr-pwrstate";
  reg = <0x2c8 4>;
  #power-domain-cells = <0>;
  #reset-cells = <0>;
  label = "dispext3_cpu";
  power-domains = <&ps_dispext3_fe>;
  status = "disabled";
 };
 ps_dispext1_fe: power-controller@2d0 {
  compatible = "apple,t6050-pmgr-pwrstate", "apple,t8103-pmgr-pwrstate";
  reg = <0x2d0 4>;
  #power-domain-cells = <0>;
  #reset-cells = <0>;
  label = "dispext1_fe";
  power-domains = <&ps_dispext1_sys>;
 };
 ps_dispext1_adma: power-controller@2d8 {
  compatible = "apple,t6050-pmgr-pwrstate", "apple,t8103-pmgr-pwrstate";
  reg = <0x2d8 4>;
  #power-domain-cells = <0>;
  #reset-cells = <0>;
  label = "dispext1_adma";
  power-domains = <&ps_dispext1_sys>;
 };
 ps_dispext1_cpu: power-controller@2e0 {
  compatible = "apple,t6050-pmgr-pwrstate", "apple,t8103-pmgr-pwrstate";
  reg = <0x2e0 4>;
  #power-domain-cells = <0>;
  #reset-cells = <0>;
  label = "dispext1_cpu";
  power-domains = <&ps_dispext1_fe>;
  status = "disabled";
 };
 ps_atc2_cio: power-controller@2e8 {
  compatible = "apple,t6050-pmgr-pwrstate", "apple,t8103-pmgr-pwrstate";
  reg = <0x2e8 4>;
  #power-domain-cells = <0>;
  #reset-cells = <0>;
  label = "atc2_cio";
  power-domains = <&ps_atc2_common>;
 };
 ps_atc2_pcie: power-controller@2f0 {
  compatible = "apple,t6050-pmgr-pwrstate", "apple,t8103-pmgr-pwrstate";
  reg = <0x2f0 4>;
  #power-domain-cells = <0>;
  #reset-cells = <0>;
  label = "atc2_pcie";
  power-domains = <&ps_atc2_common>;
 };
 ps_atc3_cio: power-controller@2f8 {
  compatible = "apple,t6050-pmgr-pwrstate", "apple,t8103-pmgr-pwrstate";
  reg = <0x2f8 4>;
  #power-domain-cells = <0>;
  #reset-cells = <0>;
  label = "atc3_cio";
  power-domains = <&ps_atc3_common>;
 };
 ps_atc3_pcie: power-controller@300 {
  compatible = "apple,t6050-pmgr-pwrstate", "apple,t8103-pmgr-pwrstate";
  reg = <0x300 4>;
  #power-domain-cells = <0>;
  #reset-cells = <0>;
  label = "atc3_pcie";
  power-domains = <&ps_atc3_common>;
 };
 ps_atc0_cio_pcie: power-controller@338 {
  compatible = "apple,t6050-pmgr-pwrstate", "apple,t8103-pmgr-pwrstate";
  reg = <0x338 4>;
  #power-domain-cells = <0>;
  #reset-cells = <0>;
  label = "atc0_cio_pcie";
  power-domains = <&ps_atc0_cio>;
 };
 ps_atc0_cio_usb: power-controller@340 {
  compatible = "apple,t6050-pmgr-pwrstate", "apple,t8103-pmgr-pwrstate";
  reg = <0x340 4>;
  #power-domain-cells = <0>;
  #reset-cells = <0>;
  label = "atc0_cio_usb";
  power-domains = <&ps_atc0_cio>;
 };
 ps_atc0_cio_auss: power-controller@348 {
  compatible = "apple,t6050-pmgr-pwrstate", "apple,t8103-pmgr-pwrstate";
  reg = <0x348 4>;
  #power-domain-cells = <0>;
  #reset-cells = <0>;
  label = "atc0_cio_auss";
  power-domains = <&ps_atc0_cio>, <&ps_auss>;
 };
 ps_atc1_cio_pcie: power-controller@350 {
  compatible = "apple,t6050-pmgr-pwrstate", "apple,t8103-pmgr-pwrstate";
  reg = <0x350 4>;
  #power-domain-cells = <0>;
  #reset-cells = <0>;
  label = "atc1_cio_pcie";
  power-domains = <&ps_atc1_cio>;
 };
 ps_atc1_cio_usb: power-controller@358 {
  compatible = "apple,t6050-pmgr-pwrstate", "apple,t8103-pmgr-pwrstate";
  reg = <0x358 4>;
  #power-domain-cells = <0>;
  #reset-cells = <0>;
  label = "atc1_cio_usb";
  power-domains = <&ps_atc1_cio>;
 };
 ps_atc1_cio_auss: power-controller@360 {
  compatible = "apple,t6050-pmgr-pwrstate", "apple,t8103-pmgr-pwrstate";
  reg = <0x360 4>;
  #power-domain-cells = <0>;
  #reset-cells = <0>;
  label = "atc1_cio_auss";
  power-domains = <&ps_atc1_cio>, <&ps_auss>;
 };
 ps_atc2_cio_pcie: power-controller@3f8 {
  compatible = "apple,t6050-pmgr-pwrstate", "apple,t8103-pmgr-pwrstate";
  reg = <0x3f8 4>;
  #power-domain-cells = <0>;
  #reset-cells = <0>;
  label = "atc2_cio_pcie";
  power-domains = <&ps_atc2_cio>;
 };
 ps_atc2_cio_usb: power-controller@400 {
  compatible = "apple,t6050-pmgr-pwrstate", "apple,t8103-pmgr-pwrstate";
  reg = <0x400 4>;
  #power-domain-cells = <0>;
  #reset-cells = <0>;
  label = "atc2_cio_usb";
  power-domains = <&ps_atc2_cio>;
 };
 ps_atc2_cio_auss: power-controller@408 {
  compatible = "apple,t6050-pmgr-pwrstate", "apple,t8103-pmgr-pwrstate";
  reg = <0x408 4>;
  #power-domain-cells = <0>;
  #reset-cells = <0>;
  label = "atc2_cio_auss";
  power-domains = <&ps_atc2_cio>, <&ps_auss>;
 };
 ps_atc3_cio_pcie: power-controller@410 {
  compatible = "apple,t6050-pmgr-pwrstate", "apple,t8103-pmgr-pwrstate";
  reg = <0x410 4>;
  #power-domain-cells = <0>;
  #reset-cells = <0>;
  label = "atc3_cio_pcie";
  power-domains = <&ps_atc3_cio>;
 };
 ps_atc3_cio_usb: power-controller@418 {
  compatible = "apple,t6050-pmgr-pwrstate", "apple,t8103-pmgr-pwrstate";
  reg = <0x418 4>;
  #power-domain-cells = <0>;
  #reset-cells = <0>;
  label = "atc3_cio_usb";
  power-domains = <&ps_atc3_cio>;
 };
 ps_atc3_cio_auss: power-controller@420 {
  compatible = "apple,t6050-pmgr-pwrstate", "apple,t8103-pmgr-pwrstate";
  reg = <0x420 4>;
  #power-domain-cells = <0>;
  #reset-cells = <0>;
  label = "atc3_cio_auss";
  power-domains = <&ps_atc3_cio>, <&ps_auss>;
 };
};
&pmgr1 {
 ps_ispsens0: power-controller@100 {
  compatible = "apple,t6050-pmgr-pwrstate", "apple,t8103-pmgr-pwrstate";
  reg = <0x100 4>;
  #power-domain-cells = <0>;
  #reset-cells = <0>;
  label = "ispsens0";
 };
 ps_global_aux_hpd_0: power-controller@108 {
  compatible = "apple,t6050-pmgr-pwrstate", "apple,t8103-pmgr-pwrstate";
  reg = <0x108 4>;
  #power-domain-cells = <0>;
  #reset-cells = <0>;
  label = "global_aux_hpd_0";
 };
 ps_global_aux_hpd_1: power-controller@110 {
  compatible = "apple,t6050-pmgr-pwrstate", "apple,t8103-pmgr-pwrstate";
  reg = <0x110 4>;
  #power-domain-cells = <0>;
  #reset-cells = <0>;
  label = "global_aux_hpd_1";
 };
 ps_apcie_gp: power-controller@118 {
  compatible = "apple,t6050-pmgr-pwrstate", "apple,t8103-pmgr-pwrstate";
  reg = <0x118 4>;
  #power-domain-cells = <0>;
  #reset-cells = <0>;
  label = "apcie_gp";
 };
 ps_apcie_st0: power-controller@128 {
  compatible = "apple,t6050-pmgr-pwrstate", "apple,t8103-pmgr-pwrstate";
  reg = <0x128 4>;
  #power-domain-cells = <0>;
  #reset-cells = <0>;
  label = "apcie_st0";
 };
 ps_apcie_st1: power-controller@130 {
  compatible = "apple,t6050-pmgr-pwrstate", "apple,t8103-pmgr-pwrstate";
  reg = <0x130 4>;
  #power-domain-cells = <0>;
  #reset-cells = <0>;
  label = "apcie_st1";
 };
 ps_ans: power-controller@140 {
  compatible = "apple,t6050-pmgr-pwrstate", "apple,t8103-pmgr-pwrstate";
  reg = <0x140 4>;
  #power-domain-cells = <0>;
  #reset-cells = <0>;
  label = "ans";
  apple,always-on;
 };
 ps_apcie_sys_gp: power-controller@148 {
  compatible = "apple,t6050-pmgr-pwrstate", "apple,t8103-pmgr-pwrstate";
  reg = <0x148 4>;
  #power-domain-cells = <0>;
  #reset-cells = <0>;
  label = "apcie_sys_gp";
  power-domains = <&ps_apcie_gp>;
 };
 ps_apcie_sys_st0: power-controller@150 {
  compatible = "apple,t6050-pmgr-pwrstate", "apple,t8103-pmgr-pwrstate";
  reg = <0x150 4>;
  #power-domain-cells = <0>;
  #reset-cells = <0>;
  label = "apcie_sys_st0";
  power-domains = <&ps_apcie_st0>, <&ps_ans>;
 };
 ps_apcie_sys_st1: power-controller@158 {
  compatible = "apple,t6050-pmgr-pwrstate", "apple,t8103-pmgr-pwrstate";
  reg = <0x158 4>;
  #power-domain-cells = <0>;
  #reset-cells = <0>;
  label = "apcie_sys_st1";
  power-domains = <&ps_apcie_st1>, <&ps_ans>;
 };
 ps_apcie_sys_gp_oc: power-controller@160 {
  compatible = "apple,t6050-pmgr-pwrstate", "apple,t8103-pmgr-pwrstate";
  reg = <0x160 4>;
  #power-domain-cells = <0>;
  #reset-cells = <0>;
  label = "apcie_sys_gp_oc";
  power-domains = <&ps_apcie_sys_gp>;
 };
 ps_apcie_sys_st0_o: power-controller@168 {
  compatible = "apple,t6050-pmgr-pwrstate", "apple,t8103-pmgr-pwrstate";
  reg = <0x168 4>;
  #power-domain-cells = <0>;
  #reset-cells = <0>;
  label = "apcie_sys_st0_o";
  power-domains = <&ps_apcie_sys_st0>;
 };
 ps_apcie_sys_st1_o: power-controller@170 {
  compatible = "apple,t6050-pmgr-pwrstate", "apple,t8103-pmgr-pwrstate";
  reg = <0x170 4>;
  #power-domain-cells = <0>;
  #reset-cells = <0>;
  label = "apcie_sys_st1_o";
  power-domains = <&ps_apcie_sys_st1>;
 };
 ps_disp_sys: power-controller@180 {
  compatible = "apple,t6050-pmgr-pwrstate", "apple,t8103-pmgr-pwrstate";
  reg = <0x180 4>;
  #power-domain-cells = <0>;
  #reset-cells = <0>;
  label = "disp_sys";
  apple,always-on;
 };
 ps_scodec: power-controller@190 {
  compatible = "apple,t6050-pmgr-pwrstate", "apple,t8103-pmgr-pwrstate";
  reg = <0x190 4>;
  #power-domain-cells = <0>;
  #reset-cells = <0>;
  label = "scodec";
 };
 ps_disp_fe: power-controller@198 {
  compatible = "apple,t6050-pmgr-pwrstate", "apple,t8103-pmgr-pwrstate";
  reg = <0x198 4>;
  #power-domain-cells = <0>;
  #reset-cells = <0>;
  label = "disp_fe";
  power-domains = <&ps_disp_sys>;
  apple,always-on;
 };
 ps_disp_adma: power-controller@1a0 {
  compatible = "apple,t6050-pmgr-pwrstate", "apple,t8103-pmgr-pwrstate";
  reg = <0x1a0 4>;
  #power-domain-cells = <0>;
  #reset-cells = <0>;
  label = "disp_adma";
  power-domains = <&ps_disp_sys>;
 };
 ps_disp_cpu: power-controller@1a8 {
  compatible = "apple,t6050-pmgr-pwrstate", "apple,t8103-pmgr-pwrstate";
  reg = <0x1a8 4>;
  #power-domain-cells = <0>;
  #reset-cells = <0>;
  label = "disp_cpu";
  power-domains = <&ps_disp_fe>;
  status = "disabled";
 };
 ps_apcie_phy_sw: power-controller@1b0 {
  compatible = "apple,t6050-pmgr-pwrstate", "apple,t8103-pmgr-pwrstate";
  reg = <0x1b0 4>;
  #power-domain-cells = <0>;
  #reset-cells = <0>;
  label = "apcie_phy_sw";
  power-domains = <&ps_apcie_sys_gp>;
 };
 ps_scodec_streaming: power-controller@1c0 {
  compatible = "apple,t6050-pmgr-pwrstate", "apple,t8103-pmgr-pwrstate";
  reg = <0x1c0 4>;
  #power-domain-cells = <0>;
  #reset-cells = <0>;
  label = "scodec_streaming";
  power-domains = <&ps_scodec>;
 };
 ps_aphy_st0_aus5_a: power-controller@240 {
  compatible = "apple,t6050-pmgr-pwrstate", "apple,t8103-pmgr-pwrstate";
  reg = <0x240 4>;
  #power-domain-cells = <0>;
  #reset-cells = <0>;
  label = "aphy_st0_aus5_a";
  power-domains = <&ps_apcie_phy_sw>;
 };
 ps_aphy_st1_aus5_a: power-controller@248 {
  compatible = "apple,t6050-pmgr-pwrstate", "apple,t8103-pmgr-pwrstate";
  reg = <0x248 4>;
  #power-domain-cells = <0>;
  #reset-cells = <0>;
  label = "aphy_st1_aus5_a";
  power-domains = <&ps_apcie_phy_sw>;
 };
 ps_aphy_gp_aus5_a: power-controller@258 {
  compatible = "apple,t6050-pmgr-pwrstate", "apple,t8103-pmgr-pwrstate";
  reg = <0x258 4>;
  #power-domain-cells = <0>;
  #reset-cells = <0>;
  label = "aphy_gp_aus5_a";
  power-domains = <&ps_apcie_phy_sw>;
 };
 ps_aphy_st0_aus5: power-controller@268 {
  compatible = "apple,t6050-pmgr-pwrstate", "apple,t8103-pmgr-pwrstate";
  reg = <0x268 4>;
  #power-domain-cells = <0>;
  #reset-cells = <0>;
  label = "aphy_st0_aus5";
  power-domains = <&ps_aphy_st0_aus5_a>;
 };
 ps_aphy_st1_aus5: power-controller@270 {
  compatible = "apple,t6050-pmgr-pwrstate", "apple,t8103-pmgr-pwrstate";
  reg = <0x270 4>;
  #power-domain-cells = <0>;
  #reset-cells = <0>;
  label = "aphy_st1_aus5";
  power-domains = <&ps_aphy_st1_aus5_a>;
 };
 ps_aphy_gp_aus5: power-controller@280 {
  compatible = "apple,t6050-pmgr-pwrstate", "apple,t8103-pmgr-pwrstate";
  reg = <0x280 4>;
  #power-domain-cells = <0>;
  #reset-cells = <0>;
  label = "aphy_gp_aus5";
  power-domains = <&ps_aphy_gp_aus5_a>;
 };
 ps_sio: power-controller@290 {
  compatible = "apple,t6050-pmgr-pwrstate", "apple,t8103-pmgr-pwrstate";
  reg = <0x290 4>;
  #power-domain-cells = <0>;
  #reset-cells = <0>;
  label = "sio";
  apple,always-on;
 };
 ps_sep: power-controller@298 {
  compatible = "apple,t6050-pmgr-pwrstate", "apple,t8103-pmgr-pwrstate";
  reg = <0x298 4>;
  #power-domain-cells = <0>;
  #reset-cells = <0>;
  label = "sep";
  apple,always-on;
 };
 ps_sio_cpu: power-controller@2a0 {
  compatible = "apple,t6050-pmgr-pwrstate", "apple,t8103-pmgr-pwrstate";
  reg = <0x2a0 4>;
  #power-domain-cells = <0>;
  #reset-cells = <0>;
  label = "sio_cpu";
  power-domains = <&ps_sio>;
  apple,always-on;
 };
 ps_fpwm0: power-controller@2a8 {
  compatible = "apple,t6050-pmgr-pwrstate", "apple,t8103-pmgr-pwrstate";
  reg = <0x2a8 4>;
  #power-domain-cells = <0>;
  #reset-cells = <0>;
  label = "fpwm0";
  power-domains = <&ps_sio>;
 };
 ps_fpwm2: power-controller@2b8 {
  compatible = "apple,t6050-pmgr-pwrstate", "apple,t8103-pmgr-pwrstate";
  reg = <0x2b8 4>;
  #power-domain-cells = <0>;
  #reset-cells = <0>;
  label = "fpwm2";
  power-domains = <&ps_sio>;
 };
 ps_i2c0: power-controller@2c0 {
  compatible = "apple,t6050-pmgr-pwrstate", "apple,t8103-pmgr-pwrstate";
  reg = <0x2c0 4>;
  #power-domain-cells = <0>;
  #reset-cells = <0>;
  label = "i2c0";
  power-domains = <&ps_sio>;
 };
 ps_i2c1: power-controller@2c8 {
  compatible = "apple,t6050-pmgr-pwrstate", "apple,t8103-pmgr-pwrstate";
  reg = <0x2c8 4>;
  #power-domain-cells = <0>;
  #reset-cells = <0>;
  label = "i2c1";
  power-domains = <&ps_sio>;
 };
 ps_i2c2: power-controller@2d0 {
  compatible = "apple,t6050-pmgr-pwrstate", "apple,t8103-pmgr-pwrstate";
  reg = <0x2d0 4>;
  #power-domain-cells = <0>;
  #reset-cells = <0>;
  label = "i2c2";
  power-domains = <&ps_sio>;
 };
 ps_i2c3: power-controller@2d8 {
  compatible = "apple,t6050-pmgr-pwrstate", "apple,t8103-pmgr-pwrstate";
  reg = <0x2d8 4>;
  #power-domain-cells = <0>;
  #reset-cells = <0>;
  label = "i2c3";
  power-domains = <&ps_sio>;
 };
 ps_i2c4: power-controller@2e0 {
  compatible = "apple,t6050-pmgr-pwrstate", "apple,t8103-pmgr-pwrstate";
  reg = <0x2e0 4>;
  #power-domain-cells = <0>;
  #reset-cells = <0>;
  label = "i2c4";
  power-domains = <&ps_sio>;
 };
 ps_i2c5: power-controller@2e8 {
  compatible = "apple,t6050-pmgr-pwrstate", "apple,t8103-pmgr-pwrstate";
  reg = <0x2e8 4>;
  #power-domain-cells = <0>;
  #reset-cells = <0>;
  label = "i2c5";
  power-domains = <&ps_sio>;
 };
 ps_i2c6: power-controller@2f0 {
  compatible = "apple,t6050-pmgr-pwrstate", "apple,t8103-pmgr-pwrstate";
  reg = <0x2f0 4>;
  #power-domain-cells = <0>;
  #reset-cells = <0>;
  label = "i2c6";
  power-domains = <&ps_sio>;
 };
 ps_i2c7: power-controller@2f8 {
  compatible = "apple,t6050-pmgr-pwrstate", "apple,t8103-pmgr-pwrstate";
  reg = <0x2f8 4>;
  #power-domain-cells = <0>;
  #reset-cells = <0>;
  label = "i2c7";
  power-domains = <&ps_sio>;
 };
 ps_i2c8: power-controller@300 {
  compatible = "apple,t6050-pmgr-pwrstate", "apple,t8103-pmgr-pwrstate";
  reg = <0x300 4>;
  #power-domain-cells = <0>;
  #reset-cells = <0>;
  label = "i2c8";
  power-domains = <&ps_sio>;
 };
 ps_spi_p: power-controller@308 {
  compatible = "apple,t6050-pmgr-pwrstate", "apple,t8103-pmgr-pwrstate";
  reg = <0x308 4>;
  #power-domain-cells = <0>;
  #reset-cells = <0>;
  label = "spi_p";
  power-domains = <&ps_sio>;
  apple,always-on;
 };
 ps_uart_p: power-controller@310 {
  compatible = "apple,t6050-pmgr-pwrstate", "apple,t8103-pmgr-pwrstate";
  reg = <0x310 4>;
  #power-domain-cells = <0>;
  #reset-cells = <0>;
  label = "uart_p";
  power-domains = <&ps_sio>;
  apple,always-on;
 };
 ps_aes: power-controller@318 {
  compatible = "apple,t6050-pmgr-pwrstate", "apple,t8103-pmgr-pwrstate";
  reg = <0x318 4>;
  #power-domain-cells = <0>;
  #reset-cells = <0>;
  label = "aes";
  power-domains = <&ps_sio>;
 };
 ps_spi0: power-controller@320 {
  compatible = "apple,t6050-pmgr-pwrstate", "apple,t8103-pmgr-pwrstate";
  reg = <0x320 4>;
  #power-domain-cells = <0>;
  #reset-cells = <0>;
  label = "spi0";
  power-domains = <&ps_spi_p>;
 };
 ps_spi1: power-controller@328 {
  compatible = "apple,t6050-pmgr-pwrstate", "apple,t8103-pmgr-pwrstate";
  reg = <0x328 4>;
  #power-domain-cells = <0>;
  #reset-cells = <0>;
  label = "spi1";
  power-domains = <&ps_spi_p>;
 };
 ps_spi2: power-controller@330 {
  compatible = "apple,t6050-pmgr-pwrstate", "apple,t8103-pmgr-pwrstate";
  reg = <0x330 4>;
  #power-domain-cells = <0>;
  #reset-cells = <0>;
  label = "spi2";
  power-domains = <&ps_spi_p>;
 };
 ps_spi3: power-controller@338 {
  compatible = "apple,t6050-pmgr-pwrstate", "apple,t8103-pmgr-pwrstate";
  reg = <0x338 4>;
  #power-domain-cells = <0>;
  #reset-cells = <0>;
  label = "spi3";
  power-domains = <&ps_spi_p>;
 };
 ps_spi4: power-controller@340 {
  compatible = "apple,t6050-pmgr-pwrstate", "apple,t8103-pmgr-pwrstate";
  reg = <0x340 4>;
  #power-domain-cells = <0>;
  #reset-cells = <0>;
  label = "spi4";
  power-domains = <&ps_spi_p>;
 };
 ps_spi5: power-controller@348 {
  compatible = "apple,t6050-pmgr-pwrstate", "apple,t8103-pmgr-pwrstate";
  reg = <0x348 4>;
  #power-domain-cells = <0>;
  #reset-cells = <0>;
  label = "spi5";
  power-domains = <&ps_spi_p>;
 };
 ps_qspi: power-controller@350 {
  compatible = "apple,t6050-pmgr-pwrstate", "apple,t8103-pmgr-pwrstate";
  reg = <0x350 4>;
  #power-domain-cells = <0>;
  #reset-cells = <0>;
  label = "qspi";
  power-domains = <&ps_spi_p>;
 };
 ps_uart_n: power-controller@358 {
  compatible = "apple,t6050-pmgr-pwrstate", "apple,t8103-pmgr-pwrstate";
  reg = <0x358 4>;
  #power-domain-cells = <0>;
  #reset-cells = <0>;
  label = "uart_n";
  power-domains = <&ps_uart_p>;
 };
 ps_uart0: power-controller@360 {
  compatible = "apple,t6050-pmgr-pwrstate", "apple,t8103-pmgr-pwrstate";
  reg = <0x360 4>;
  #power-domain-cells = <0>;
  #reset-cells = <0>;
  label = "uart0";
  power-domains = <&ps_uart_p>;
 };
 ps_uart1: power-controller@368 {
  compatible = "apple,t6050-pmgr-pwrstate", "apple,t8103-pmgr-pwrstate";
  reg = <0x368 4>;
  #power-domain-cells = <0>;
  #reset-cells = <0>;
  label = "uart1";
  power-domains = <&ps_uart_p>;
 };
 ps_uart2: power-controller@370 {
  compatible = "apple,t6050-pmgr-pwrstate", "apple,t8103-pmgr-pwrstate";
  reg = <0x370 4>;
  #power-domain-cells = <0>;
  #reset-cells = <0>;
  label = "uart2";
  power-domains = <&ps_uart_p>;
 };
 ps_uart3: power-controller@378 {
  compatible = "apple,t6050-pmgr-pwrstate", "apple,t8103-pmgr-pwrstate";
  reg = <0x378 4>;
  #power-domain-cells = <0>;
  #reset-cells = <0>;
  label = "uart3";
  power-domains = <&ps_uart_p>;
 };
 ps_uart4: power-controller@380 {
  compatible = "apple,t6050-pmgr-pwrstate", "apple,t8103-pmgr-pwrstate";
  reg = <0x380 4>;
  #power-domain-cells = <0>;
  #reset-cells = <0>;
  label = "uart4";
  power-domains = <&ps_uart_p>;
 };
 ps_uart5: power-controller@388 {
  compatible = "apple,t6050-pmgr-pwrstate", "apple,t8103-pmgr-pwrstate";
  reg = <0x388 4>;
  #power-domain-cells = <0>;
  #reset-cells = <0>;
  label = "uart5";
  power-domains = <&ps_uart_p>;
 };
 ps_uart6: power-controller@390 {
  compatible = "apple,t6050-pmgr-pwrstate", "apple,t8103-pmgr-pwrstate";
  reg = <0x390 4>;
  #power-domain-cells = <0>;
  #reset-cells = <0>;
  label = "uart6";
  power-domains = <&ps_uart_p>;
 };
 ps_isp_sys: power-controller@3a0 {
  compatible = "apple,t6050-pmgr-pwrstate", "apple,t8103-pmgr-pwrstate";
  reg = <0x3a0 4>;
  #power-domain-cells = <0>;
  #reset-cells = <0>;
  label = "isp_sys";
 };
 ps_ane_sys: power-controller@3a8 {
  compatible = "apple,t6050-pmgr-pwrstate", "apple,t8103-pmgr-pwrstate";
  reg = <0x3a8 4>;
  #power-domain-cells = <0>;
  #reset-cells = <0>;
  label = "ane_sys";
 };
 ps_ane_mpm: power-controller@3c0 {
  compatible = "apple,t6050-pmgr-pwrstate", "apple,t8103-pmgr-pwrstate";
  reg = <0x3c0 4>;
  #power-domain-cells = <0>;
  #reset-cells = <0>;
  label = "ane_mpm";
  power-domains = <&ps_ane_sys>;
 };
 ps_ane_cpu: power-controller@3c8 {
  compatible = "apple,t6050-pmgr-pwrstate", "apple,t8103-pmgr-pwrstate";
  reg = <0x3c8 4>;
  #power-domain-cells = <0>;
  #reset-cells = <0>;
  label = "ane_cpu";
  power-domains = <&ps_ane_sys>;
 };
 ps_ane_tdbase: power-controller@3d0 {
  compatible = "apple,t6050-pmgr-pwrstate", "apple,t8103-pmgr-pwrstate";
  reg = <0x3d0 4>;
  #power-domain-cells = <0>;
  #reset-cells = <0>;
  label = "ane_tdbase";
  power-domains = <&ps_ane_sys>;
 };
};
&pmgr_mini {
 ps_debug_gated: power-controller@58 {
  compatible = "apple,t6050-pmgr-pwrstate", "apple,t8103-pmgr-pwrstate";
  reg = <0x58 4>;
  #power-domain-cells = <0>;
  #reset-cells = <0>;
  label = "debug_gated";
  apple,always-on;
 };
 ps_nub_spmi_a0: power-controller@60 {
  compatible = "apple,t6050-pmgr-pwrstate", "apple,t8103-pmgr-pwrstate";
  reg = <0x60 4>;
  #power-domain-cells = <0>;
  #reset-cells = <0>;
  label = "nub_spmi_a0";
  apple,always-on;
 };
 ps_nub_spmi_a1: power-controller@68 {
  compatible = "apple,t6050-pmgr-pwrstate", "apple,t8103-pmgr-pwrstate";
  reg = <0x68 4>;
  #power-domain-cells = <0>;
  #reset-cells = <0>;
  label = "nub_spmi_a1";
  apple,always-on;
 };
 ps_nub_spmi_a2: power-controller@70 {
  compatible = "apple,t6050-pmgr-pwrstate", "apple,t8103-pmgr-pwrstate";
  reg = <0x70 4>;
  #power-domain-cells = <0>;
  #reset-cells = <0>;
  label = "nub_spmi_a2";
  apple,always-on;
 };
 ps_nub_dock_channel: power-controller@80 {
  compatible = "apple,t6050-pmgr-pwrstate", "apple,t8103-pmgr-pwrstate";
  reg = <0x80 4>;
  #power-domain-cells = <0>;
  #reset-cells = <0>;
  label = "nub_dock_channel";
  apple,always-on;
 };
 ps_nub_gpio: power-controller@88 {
  compatible = "apple,t6050-pmgr-pwrstate", "apple,t8103-pmgr-pwrstate";
  reg = <0x88 4>;
  #power-domain-cells = <0>;
  #reset-cells = <0>;
  label = "nub_gpio";
  apple,always-on;
 };
 ps_atc0_common_dp_0: power-controller@98 {
  compatible = "apple,t6050-pmgr-pwrstate", "apple,t8103-pmgr-pwrstate";
  reg = <0x98 4>;
  #power-domain-cells = <0>;
  #reset-cells = <0>;
  label = "atc0_common_dp_0";
 };
 ps_atc0_common_dp_1: power-controller@a0 {
  compatible = "apple,t6050-pmgr-pwrstate", "apple,t8103-pmgr-pwrstate";
  reg = <0xa0 4>;
  #power-domain-cells = <0>;
  #reset-cells = <0>;
  label = "atc0_common_dp_1";
 };
 ps_atc0_common_dp_2: power-controller@a8 {
  compatible = "apple,t6050-pmgr-pwrstate", "apple,t8103-pmgr-pwrstate";
  reg = <0xa8 4>;
  #power-domain-cells = <0>;
  #reset-cells = <0>;
  label = "atc0_common_dp_2";
 };
 ps_atc0_common_dp_3: power-controller@b0 {
  compatible = "apple,t6050-pmgr-pwrstate", "apple,t8103-pmgr-pwrstate";
  reg = <0xb0 4>;
  #power-domain-cells = <0>;
  #reset-cells = <0>;
  label = "atc0_common_dp_3";
 };
 ps_atc1_common_dp_0: power-controller@b8 {
  compatible = "apple,t6050-pmgr-pwrstate", "apple,t8103-pmgr-pwrstate";
  reg = <0xb8 4>;
  #power-domain-cells = <0>;
  #reset-cells = <0>;
  label = "atc1_common_dp_0";
 };
 ps_atc1_common_dp_1: power-controller@c0 {
  compatible = "apple,t6050-pmgr-pwrstate", "apple,t8103-pmgr-pwrstate";
  reg = <0xc0 4>;
  #power-domain-cells = <0>;
  #reset-cells = <0>;
  label = "atc1_common_dp_1";
 };
 ps_atc1_common_dp_2: power-controller@c8 {
  compatible = "apple,t6050-pmgr-pwrstate", "apple,t8103-pmgr-pwrstate";
  reg = <0xc8 4>;
  #power-domain-cells = <0>;
  #reset-cells = <0>;
  label = "atc1_common_dp_2";
 };
 ps_atc1_common_dp_3: power-controller@d0 {
  compatible = "apple,t6050-pmgr-pwrstate", "apple,t8103-pmgr-pwrstate";
  reg = <0xd0 4>;
  #power-domain-cells = <0>;
  #reset-cells = <0>;
  label = "atc1_common_dp_3";
 };
 ps_atc2_common_dp_0: power-controller@d8 {
  compatible = "apple,t6050-pmgr-pwrstate", "apple,t8103-pmgr-pwrstate";
  reg = <0xd8 4>;
  #power-domain-cells = <0>;
  #reset-cells = <0>;
  label = "atc2_common_dp_0";
 };
 ps_atc2_common_dp_1: power-controller@e0 {
  compatible = "apple,t6050-pmgr-pwrstate", "apple,t8103-pmgr-pwrstate";
  reg = <0xe0 4>;
  #power-domain-cells = <0>;
  #reset-cells = <0>;
  label = "atc2_common_dp_1";
 };
 ps_atc2_common_dp_2: power-controller@e8 {
  compatible = "apple,t6050-pmgr-pwrstate", "apple,t8103-pmgr-pwrstate";
  reg = <0xe8 4>;
  #power-domain-cells = <0>;
  #reset-cells = <0>;
  label = "atc2_common_dp_2";
 };
 ps_atc2_common_dp_3: power-controller@f0 {
  compatible = "apple,t6050-pmgr-pwrstate", "apple,t8103-pmgr-pwrstate";
  reg = <0xf0 4>;
  #power-domain-cells = <0>;
  #reset-cells = <0>;
  label = "atc2_common_dp_3";
 };
 ps_atc3_common_dp_0: power-controller@f8 {
  compatible = "apple,t6050-pmgr-pwrstate", "apple,t8103-pmgr-pwrstate";
  reg = <0xf8 4>;
  #power-domain-cells = <0>;
  #reset-cells = <0>;
  label = "atc3_common_dp_0";
 };
 ps_atc3_common_dp_1: power-controller@100 {
  compatible = "apple,t6050-pmgr-pwrstate", "apple,t8103-pmgr-pwrstate";
  reg = <0x100 4>;
  #power-domain-cells = <0>;
  #reset-cells = <0>;
  label = "atc3_common_dp_1";
 };
 ps_atc3_common_dp_2: power-controller@108 {
  compatible = "apple,t6050-pmgr-pwrstate", "apple,t8103-pmgr-pwrstate";
  reg = <0x108 4>;
  #power-domain-cells = <0>;
  #reset-cells = <0>;
  label = "atc3_common_dp_2";
 };
 ps_atc3_common_dp_3: power-controller@110 {
  compatible = "apple,t6050-pmgr-pwrstate", "apple,t8103-pmgr-pwrstate";
  reg = <0x110 4>;
  #power-domain-cells = <0>;
  #reset-cells = <0>;
  label = "atc3_common_dp_3";
 };
 ps_nub_spmi_ahb: power-controller@118 {
  compatible = "apple,t6050-pmgr-pwrstate", "apple,t8103-pmgr-pwrstate";
  reg = <0x118 4>;
  #power-domain-cells = <0>;
  #reset-cells = <0>;
  label = "nub_spmi_ahb";
  apple,always-on;
 };
 ps_nub_spmi0: power-controller@120 {
  compatible = "apple,t6050-pmgr-pwrstate", "apple,t8103-pmgr-pwrstate";
  reg = <0x120 4>;
  #power-domain-cells = <0>;
  #reset-cells = <0>;
  label = "nub_spmi0";
  power-domains = <&ps_nub_spmi_ahb>;
  apple,always-on;
 };
 ps_nub_spmi1: power-controller@128 {
  compatible = "apple,t6050-pmgr-pwrstate", "apple,t8103-pmgr-pwrstate";
  reg = <0x128 4>;
  #power-domain-cells = <0>;
  #reset-cells = <0>;
  label = "nub_spmi1";
  power-domains = <&ps_nub_spmi_ahb>;
  apple,always-on;
 };
 ps_nub_spmi2: power-controller@130 {
  compatible = "apple,t6050-pmgr-pwrstate", "apple,t8103-pmgr-pwrstate";
  reg = <0x130 4>;
  #power-domain-cells = <0>;
  #reset-cells = <0>;
  label = "nub_spmi2";
  power-domains = <&ps_nub_spmi_ahb>;
  apple,always-on;
 };
 ps_nub_spmi3: power-controller@138 {
  compatible = "apple,t6050-pmgr-pwrstate", "apple,t8103-pmgr-pwrstate";
  reg = <0x138 4>;
  #power-domain-cells = <0>;
  #reset-cells = <0>;
  label = "nub_spmi3";
  power-domains = <&ps_nub_spmi_ahb>;
  apple,always-on;
 };
 ps_nub_spmi4: power-controller@140 {
  compatible = "apple,t6050-pmgr-pwrstate", "apple,t8103-pmgr-pwrstate";
  reg = <0x140 4>;
  #power-domain-cells = <0>;
  #reset-cells = <0>;
  label = "nub_spmi4";
  power-domains = <&ps_nub_spmi_ahb>;
  apple,always-on;
 };
 ps_atc0_usb_aon: power-controller@148 {
  compatible = "apple,t6050-pmgr-pwrstate", "apple,t8103-pmgr-pwrstate";
  reg = <0x148 4>;
  #power-domain-cells = <0>;
  #reset-cells = <0>;
  label = "atc0_usb_aon";
 };
 ps_atc0_usb: power-controller@150 {
  compatible = "apple,t6050-pmgr-pwrstate", "apple,t8103-pmgr-pwrstate";
  reg = <0x150 4>;
  #power-domain-cells = <0>;
  #reset-cells = <0>;
  label = "atc0_usb";
  power-domains = <&ps_atc0_common>, <&ps_atc0_usb_aon>;
 };
 ps_atc0_phymxwrap: power-controller@158 {
  compatible = "apple,t6050-pmgr-pwrstate", "apple,t8103-pmgr-pwrstate";
  reg = <0x158 4>;
  #power-domain-cells = <0>;
  #reset-cells = <0>;
  label = "atc0_phymxwrap";
  power-domains = <&ps_atc0_common>, <&ps_atc0_usb_aon>;
 };
 ps_atc1_usb_aon: power-controller@160 {
  compatible = "apple,t6050-pmgr-pwrstate", "apple,t8103-pmgr-pwrstate";
  reg = <0x160 4>;
  #power-domain-cells = <0>;
  #reset-cells = <0>;
  label = "atc1_usb_aon";
 };
 ps_atc1_usb: power-controller@168 {
  compatible = "apple,t6050-pmgr-pwrstate", "apple,t8103-pmgr-pwrstate";
  reg = <0x168 4>;
  #power-domain-cells = <0>;
  #reset-cells = <0>;
  label = "atc1_usb";
  power-domains = <&ps_atc1_common>, <&ps_atc1_usb_aon>;
 };
 ps_atc1_phymxwrap: power-controller@170 {
  compatible = "apple,t6050-pmgr-pwrstate", "apple,t8103-pmgr-pwrstate";
  reg = <0x170 4>;
  #power-domain-cells = <0>;
  #reset-cells = <0>;
  label = "atc1_phymxwrap";
  power-domains = <&ps_atc1_common>, <&ps_atc1_usb_aon>;
 };
 ps_atc2_usb_aon: power-controller@178 {
  compatible = "apple,t6050-pmgr-pwrstate", "apple,t8103-pmgr-pwrstate";
  reg = <0x178 4>;
  #power-domain-cells = <0>;
  #reset-cells = <0>;
  label = "atc2_usb_aon";
 };
 ps_atc2_usb: power-controller@180 {
  compatible = "apple,t6050-pmgr-pwrstate", "apple,t8103-pmgr-pwrstate";
  reg = <0x180 4>;
  #power-domain-cells = <0>;
  #reset-cells = <0>;
  label = "atc2_usb";
  power-domains = <&ps_atc2_common>, <&ps_atc2_usb_aon>;
 };
 ps_atc2_phymxwrap: power-controller@188 {
  compatible = "apple,t6050-pmgr-pwrstate", "apple,t8103-pmgr-pwrstate";
  reg = <0x188 4>;
  #power-domain-cells = <0>;
  #reset-cells = <0>;
  label = "atc2_phymxwrap";
  power-domains = <&ps_atc2_common>, <&ps_atc2_usb_aon>;
 };
 ps_atc3_usb_aon: power-controller@190 {
  compatible = "apple,t6050-pmgr-pwrstate", "apple,t8103-pmgr-pwrstate";
  reg = <0x190 4>;
  #power-domain-cells = <0>;
  #reset-cells = <0>;
  label = "atc3_usb_aon";
 };
 ps_atc3_usb: power-controller@198 {
  compatible = "apple,t6050-pmgr-pwrstate", "apple,t8103-pmgr-pwrstate";
  reg = <0x198 4>;
  #power-domain-cells = <0>;
  #reset-cells = <0>;
  label = "atc3_usb";
  power-domains = <&ps_atc3_common>, <&ps_atc3_usb_aon>;
 };
 ps_atc3_phymxwrap: power-controller@1a0 {
  compatible = "apple,t6050-pmgr-pwrstate", "apple,t8103-pmgr-pwrstate";
  reg = <0x1a0 4>;
  #power-domain-cells = <0>;
  #reset-cells = <0>;
  label = "atc3_phymxwrap";
  power-domains = <&ps_atc3_common>, <&ps_atc3_usb_aon>;
 };
 ps_smc_i2cm0: power-controller@8028 {
  compatible = "apple,t6050-pmgr-pwrstate", "apple,t8103-pmgr-pwrstate";
  reg = <0x8028 4>;
  #power-domain-cells = <0>;
  #reset-cells = <0>;
  label = "smc_i2cm0";
 };
 ps_smc_i2cm1: power-controller@8030 {
  compatible = "apple,t6050-pmgr-pwrstate", "apple,t8103-pmgr-pwrstate";
  reg = <0x8030 4>;
  #power-domain-cells = <0>;
  #reset-cells = <0>;
  label = "smc_i2cm1";
 };
 ps_smc_i2cm2: power-controller@8038 {
  compatible = "apple,t6050-pmgr-pwrstate", "apple,t8103-pmgr-pwrstate";
  reg = <0x8038 4>;
  #power-domain-cells = <0>;
  #reset-cells = <0>;
  label = "smc_i2cm2";
 };
 ps_smc_i2cm3: power-controller@8040 {
  compatible = "apple,t6050-pmgr-pwrstate", "apple,t8103-pmgr-pwrstate";
  reg = <0x8040 4>;
  #power-domain-cells = <0>;
  #reset-cells = <0>;
  label = "smc_i2cm3";
 };
 ps_smc_i2cm4: power-controller@8048 {
  compatible = "apple,t6050-pmgr-pwrstate", "apple,t8103-pmgr-pwrstate";
  reg = <0x8048 4>;
  #power-domain-cells = <0>;
  #reset-cells = <0>;
  label = "smc_i2cm4";
 };
 ps_smc_i2cm5: power-controller@8050 {
  compatible = "apple,t6050-pmgr-pwrstate", "apple,t8103-pmgr-pwrstate";
  reg = <0x8050 4>;
  #power-domain-cells = <0>;
  #reset-cells = <0>;
  label = "smc_i2cm5";
 };
 ps_smc_i2cm6: power-controller@8058 {
  compatible = "apple,t6050-pmgr-pwrstate", "apple,t8103-pmgr-pwrstate";
  reg = <0x8058 4>;
  #power-domain-cells = <0>;
  #reset-cells = <0>;
  label = "smc_i2cm6";
 };
};
&pmgr_gfx {
 ps_gpx: power-controller@0 {
  compatible = "apple,t6050-pmgr-pwrstate", "apple,t8103-pmgr-pwrstate";
  reg = <0x0 4>;
  #power-domain-cells = <0>;
  #reset-cells = <0>;
  label = "gpx";
  apple,always-on;
 };
 ps_afr: power-controller@100 {
  compatible = "apple,t6050-pmgr-pwrstate", "apple,t8103-pmgr-pwrstate";
  reg = <0x100 4>;
  #power-domain-cells = <0>;
  #reset-cells = <0>;
  label = "afr";
  apple,always-on;
 };
 ps_cs: power-controller@108 {
  compatible = "apple,t6050-pmgr-pwrstate", "apple,t8103-pmgr-pwrstate";
  reg = <0x108 4>;
  #power-domain-cells = <0>;
  #reset-cells = <0>;
  label = "cs";
  power-domains = <&ps_afr>;
  apple,always-on;
 };
 ps_gfx: power-controller@110 {
  compatible = "apple,t6050-pmgr-pwrstate", "apple,t8103-pmgr-pwrstate";
  reg = <0x110 4>;
  #power-domain-cells = <0>;
  #reset-cells = <0>;
  label = "gfx";
  power-domains = <&ps_afr>, <&ps_gpx>;
 };
};
&pmgr_die1 {
 ps_aic_gfx: power-controller@108 {
  compatible = "apple,t6050-pmgr-pwrstate", "apple,t8103-pmgr-pwrstate";
  reg = <0x108 4>;
  #power-domain-cells = <0>;
  #reset-cells = <0>;
  label = "aic_gfx";
  apple,always-on;
 };
 ps_pms_gfx_c1ppt: power-controller@110 {
  compatible = "apple,t6050-pmgr-pwrstate", "apple,t8103-pmgr-pwrstate";
  reg = <0x110 4>;
  #power-domain-cells = <0>;
  #reset-cells = <0>;
  label = "pms_gfx_c1ppt";
  apple,always-on;
 };
 ps_soc_dpe_gfx: power-controller@118 {
  compatible = "apple,t6050-pmgr-pwrstate", "apple,t8103-pmgr-pwrstate";
  reg = <0x118 4>;
  #power-domain-cells = <0>;
  #reset-cells = <0>;
  label = "soc_dpe_gfx";
  apple,always-on;
 };
 ps_venc0_sys: power-controller@1c0 {
  compatible = "apple,t6050-pmgr-pwrstate", "apple,t8103-pmgr-pwrstate";
  reg = <0x1c0 4>;
  #power-domain-cells = <0>;
  #reset-cells = <0>;
  label = "venc0_sys";
 };
 ps_msr0: power-controller@1c8 {
  compatible = "apple,t6050-pmgr-pwrstate", "apple,t8103-pmgr-pwrstate";
  reg = <0x1c8 4>;
  #power-domain-cells = <0>;
  #reset-cells = <0>;
  label = "msr0";
 };
 ps_jpg: power-controller@1d0 {
  compatible = "apple,t6050-pmgr-pwrstate", "apple,t8103-pmgr-pwrstate";
  reg = <0x1d0 4>;
  #power-domain-cells = <0>;
  #reset-cells = <0>;
  label = "jpg";
 };
 ps_avd_sys: power-controller@1d8 {
  compatible = "apple,t6050-pmgr-pwrstate", "apple,t8103-pmgr-pwrstate";
  reg = <0x1d8 4>;
  #power-domain-cells = <0>;
  #reset-cells = <0>;
  label = "avd_sys";
 };
 ps_prores: power-controller@1e0 {
  compatible = "apple,t6050-pmgr-pwrstate", "apple,t8103-pmgr-pwrstate";
  reg = <0x1e0 4>;
  #power-domain-cells = <0>;
  #reset-cells = <0>;
  label = "prores";
 };
 ps_venc1_sys: power-controller@1f0 {
  compatible = "apple,t6050-pmgr-pwrstate", "apple,t8103-pmgr-pwrstate";
  reg = <0x1f0 4>;
  #power-domain-cells = <0>;
  #reset-cells = <0>;
  label = "venc1_sys";
 };
 ps_msr1: power-controller@1f8 {
  compatible = "apple,t6050-pmgr-pwrstate", "apple,t8103-pmgr-pwrstate";
  reg = <0x1f8 4>;
  #power-domain-cells = <0>;
  #reset-cells = <0>;
  label = "msr1";
 };
 ps_msr0_ase_core: power-controller@200 {
  compatible = "apple,t6050-pmgr-pwrstate", "apple,t8103-pmgr-pwrstate";
  reg = <0x200 4>;
  #power-domain-cells = <0>;
  #reset-cells = <0>;
  label = "msr0_ase_core";
  power-domains = <&ps_msr0>;
 };
 ps_msr1_ase_core: power-controller@208 {
  compatible = "apple,t6050-pmgr-pwrstate", "apple,t8103-pmgr-pwrstate";
  reg = <0x208 4>;
  #power-domain-cells = <0>;
  #reset-cells = <0>;
  label = "msr1_ase_core";
  power-domains = <&ps_msr1>;
 };
 ps_venc0_dma: power-controller@8000 {
  compatible = "apple,t6050-pmgr-pwrstate", "apple,t8103-pmgr-pwrstate";
  reg = <0x8000 4>;
  #power-domain-cells = <0>;
  #reset-cells = <0>;
  label = "venc0_dma";
  power-domains = <&ps_venc0_sys>;
 };
 ps_venc0_pipe4: power-controller@8008 {
  compatible = "apple,t6050-pmgr-pwrstate", "apple,t8103-pmgr-pwrstate";
  reg = <0x8008 4>;
  #power-domain-cells = <0>;
  #reset-cells = <0>;
  label = "venc0_pipe4";
  power-domains = <&ps_venc0_dma>;
 };
 ps_venc0_pipe5: power-controller@8010 {
  compatible = "apple,t6050-pmgr-pwrstate", "apple,t8103-pmgr-pwrstate";
  reg = <0x8010 4>;
  #power-domain-cells = <0>;
  #reset-cells = <0>;
  label = "venc0_pipe5";
  power-domains = <&ps_venc0_dma>;
 };
 ps_venc0_me0: power-controller@8018 {
  compatible = "apple,t6050-pmgr-pwrstate", "apple,t8103-pmgr-pwrstate";
  reg = <0x8018 4>;
  #power-domain-cells = <0>;
  #reset-cells = <0>;
  label = "venc0_me0";
  power-domains = <&ps_venc0_dma>;
 };
 ps_venc0_me1: power-controller@8020 {
  compatible = "apple,t6050-pmgr-pwrstate", "apple,t8103-pmgr-pwrstate";
  reg = <0x8020 4>;
  #power-domain-cells = <0>;
  #reset-cells = <0>;
  label = "venc0_me1";
  power-domains = <&ps_venc0_me0>;
 };
 ps_venc1_dma: power-controller@8028 {
  compatible = "apple,t6050-pmgr-pwrstate", "apple,t8103-pmgr-pwrstate";
  reg = <0x8028 4>;
  #power-domain-cells = <0>;
  #reset-cells = <0>;
  label = "venc1_dma";
  power-domains = <&ps_venc1_sys>;
 };
 ps_venc1_pipe4: power-controller@8030 {
  compatible = "apple,t6050-pmgr-pwrstate", "apple,t8103-pmgr-pwrstate";
  reg = <0x8030 4>;
  #power-domain-cells = <0>;
  #reset-cells = <0>;
  label = "venc1_pipe4";
  power-domains = <&ps_venc1_dma>;
 };
 ps_venc1_pipe5: power-controller@8038 {
  compatible = "apple,t6050-pmgr-pwrstate", "apple,t8103-pmgr-pwrstate";
  reg = <0x8038 4>;
  #power-domain-cells = <0>;
  #reset-cells = <0>;
  label = "venc1_pipe5";
  power-domains = <&ps_venc1_dma>;
 };
 ps_venc1_me0: power-controller@8040 {
  compatible = "apple,t6050-pmgr-pwrstate", "apple,t8103-pmgr-pwrstate";
  reg = <0x8040 4>;
  #power-domain-cells = <0>;
  #reset-cells = <0>;
  label = "venc1_me0";
  power-domains = <&ps_venc1_dma>;
 };
 ps_venc1_me1: power-controller@8048 {
  compatible = "apple,t6050-pmgr-pwrstate", "apple,t8103-pmgr-pwrstate";
  reg = <0x8048 4>;
  #power-domain-cells = <0>;
  #reset-cells = <0>;
  label = "venc1_me1";
  power-domains = <&ps_venc1_me0>;
 };
};
&pmgr_die1_mini {
 ps_debug_gfx_gated: power-controller@58 {
  compatible = "apple,t6050-pmgr-pwrstate", "apple,t8103-pmgr-pwrstate";
  reg = <0x58 4>;
  #power-domain-cells = <0>;
  #reset-cells = <0>;
  label = "debug_gfx_gated";
  apple,always-on;
 };
 ps_nub_gfx_gpio: power-controller@68 {
  compatible = "apple,t6050-pmgr-pwrstate", "apple,t8103-pmgr-pwrstate";
  reg = <0x68 4>;
  #power-domain-cells = <0>;
  #reset-cells = <0>;
  label = "nub_gfx_gpio";
  apple,always-on;
 };
};

/ {
 compatible = "apple,j716c", "apple,t6050", "apple,arm-platform";
 model = "Apple MacBook Pro (16-inch, M5 Max)";
 aliases {
  serial0 = &serial0;
 };
 chosen {
  #address-cells = <2>;
  #size-cells = <2>;
  ranges;
  stdout-path = "serial0";
 };
 memory@10000000000 {
  device_type = "memory";
  reg = <0x100 0 0x2 0>;
 };
};
&serial0 {
 status = "okay";
};
